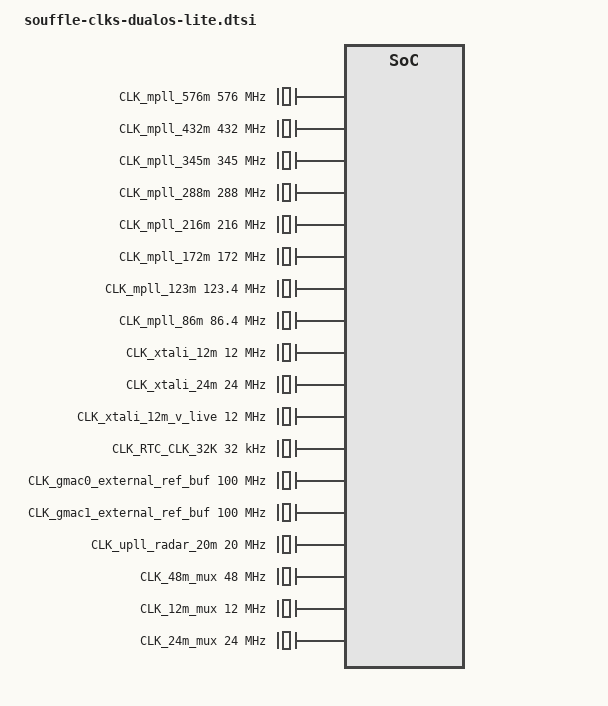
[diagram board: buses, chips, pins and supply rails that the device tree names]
/*
* souffle-clks-dualos-lite.dtsi- Sigmastar
*
* Copyright (c) [2019~2020] SigmaStar Technology.
*
*
* This software is licensed under the terms of the GNU General Public
* License version 2, as published by the Free Software Foundation, and
* may be copied, distributed, and modified under those terms.
*
* This program is distributed in the hope that it will be useful,
* but WITHOUT ANY WARRANTY; without even the implied warranty of
* MERCHANTABILITY or FITNESS FOR A PARTICULAR PURPOSE.  See the
* GNU General Public License version 2 for more details.
*
*/

/* generated by CLK_DT_GEN_5.2 */
/* CLK FILENAME: infinity6f\infinity6f_clock_table.xls */
/* REG FILENAME: infinity6f\infinity6f_reg_CLKGEN.xls, infinity6f\infinity6f_reg_CLKGEN2.xls, infinity6f\infinity6f_reg_pm_sleep.xls, infinity6f\infinity6f_reg_block.xls, infinity6f\infinity6f_reg_chiptop.xls */

CLK_VOID: CLK_VOID {
    #clock-cells = <0>;
    compatible = "fixed-clock";
    clock-frequency = <1>;
};

CLK_mpll_576m: CLK_mpll_576m {
    #clock-cells = <0>;
    compatible = "fixed-clock";
    clock-frequency = <576000000>;
};

CLK_upll_960m: CLK_upll_960m {
    #clock-cells = <0>;
    compatible = "sstar,complex-clock";
    clocks = <&CLK_VOID>;
    clock-frequency = <960000000>;
};

CLK_upll_480m: CLK_upll_480m {
    #clock-cells = <0>;
    compatible = "sstar,complex-clock";
    clocks = <&CLK_upll_960m>;
    clock-frequency = <480000000>;
};

CLK_mpll_432m: CLK_mpll_432m {
    #clock-cells = <0>;
    compatible = "fixed-clock";
    clock-frequency = <432000000>;
};

CLK_upll_384m: CLK_upll_384m {
    #clock-cells = <0>;
    compatible = "sstar,complex-clock";
    clocks = <&CLK_upll_960m>;
    clock-frequency = <384000000>;
};

CLK_aupll_384m: CLK_aupll_384m {
    #clock-cells = <0>;
    compatible = "sstar,complex-clock";
    clocks = <&CLK_mpll_432m>;
    clock-frequency = <384000000>;
};

CLK_bachpll_384m: CLK_bachpll_384m {
    #clock-cells = <0>;
    compatible = "sstar,complex-clock";
    clocks = <&CLK_VOID>;
    clock-frequency = <384000000>;
};

CLK_mpll_345m: CLK_mpll_345m {
    #clock-cells = <0>;
    compatible = "fixed-clock";
    clock-frequency = <345000000>;
};

CLK_upll_320m: CLK_upll_320m {
    #clock-cells = <0>;
    compatible = "sstar,complex-clock";
    clocks = <&CLK_upll_960m>;
    clock-frequency = <320000000>;
};

CLK_mpll_288m: CLK_mpll_288m {
    #clock-cells = <0>;
    compatible = "fixed-clock";
    clock-frequency = <288000000>;
};

CLK_mpll_216m: CLK_mpll_216m {
    #clock-cells = <0>;
    compatible = "fixed-clock";
    clock-frequency = <216000000>;
};

CLK_mpll_172m: CLK_mpll_172m {
    #clock-cells = <0>;
    compatible = "fixed-clock";
    clock-frequency = <172000000>;
};

CLK_mpll_123m: CLK_mpll_123m {
    #clock-cells = <0>;
    compatible = "fixed-clock";
    clock-frequency = <123400000>;
};

CLK_mpll_86m: CLK_mpll_86m {
    #clock-cells = <0>;
    compatible = "fixed-clock";
    clock-frequency = <86400000>;
};

CLK_upll_480m_div2: CLK_upll_480m_div2 {
    #clock-cells = <0>;
    compatible = "fixed-factor-clock";
    clocks = <&CLK_upll_480m>;
    clock-div = <2>;
    clock-mult = <1>;
};

CLK_upll_384m_div2: CLK_upll_384m_div2 {
    #clock-cells = <0>;
    compatible = "fixed-factor-clock";
    clocks = <&CLK_upll_384m>;
    clock-div = <2>;
    clock-mult = <1>;
};

CLK_mpll_288m_div2: CLK_mpll_288m_div2 {
    #clock-cells = <0>;
    compatible = "fixed-factor-clock";
    clocks = <&CLK_mpll_288m>;
    clock-div = <2>;
    clock-mult = <1>;
};

CLK_mpll_288m_div4: CLK_mpll_288m_div4 {
    #clock-cells = <0>;
    compatible = "fixed-factor-clock";
    clocks = <&CLK_mpll_288m>;
    clock-div = <4>;
    clock-mult = <1>;
};

CLK_mpll_288m_div8: CLK_mpll_288m_div8 {
    #clock-cells = <0>;
    compatible = "fixed-factor-clock";
    clocks = <&CLK_mpll_288m>;
    clock-div = <8>;
    clock-mult = <1>;
};

CLK_mpll_432m_div4: CLK_mpll_432m_div4 {
    #clock-cells = <0>;
    compatible = "fixed-factor-clock";
    clocks = <&CLK_mpll_432m>;
    clock-div = <4>;
    clock-mult = <1>;
};

CLK_mpll_432m_div8: CLK_mpll_432m_div8 {
    #clock-cells = <0>;
    compatible = "fixed-factor-clock";
    clocks = <&CLK_mpll_432m>;
    clock-div = <8>;
    clock-mult = <1>;
};

/* CLK_mpll_432m_div16: CLK_mpll_432m_div16 {
    #clock-cells = <0>;
    compatible = "fixed-factor-clock";
    clocks = <&CLK_mpll_432m>;
    clock-div = <16>;
    clock-mult = <1>;
}; */

/* CLK_mpll_123m_div2: CLK_mpll_123m_div2 {
    #clock-cells = <0>;
    compatible = "fixed-factor-clock";
    clocks = <&CLK_mpll_123m>;
    clock-div = <2>;
    clock-mult = <1>;
}; */

CLK_mpll_86m_div2: CLK_mpll_86m_div2 {
    #clock-cells = <0>;
    compatible = "fixed-factor-clock";
    clocks = <&CLK_mpll_86m>;
    clock-div = <2>;
    clock-mult = <1>;
};

/* CLK_mpll_86m_div4: CLK_mpll_86m_div4 {
    #clock-cells = <0>;
    compatible = "fixed-factor-clock";
    clocks = <&CLK_mpll_86m>;
    clock-div = <4>;
    clock-mult = <1>;
}; */

/* CLK_mpll_86m_div16: CLK_mpll_86m_div16 {
    #clock-cells = <0>;
    compatible = "fixed-factor-clock";
    clocks = <&CLK_mpll_86m>;
    clock-div = <16>;
    clock-mult = <1>;
}; */

CLK_upll_384m_div8: CLK_upll_384m_div8 {
    #clock-cells = <0>;
    compatible = "fixed-factor-clock";
    clocks = <&CLK_upll_384m>;
    clock-div = <8>;
    clock-mult = <1>;
};

CLK_upll_320m_div2: CLK_upll_320m_div2 {
    #clock-cells = <0>;
    compatible = "fixed-factor-clock";
    clocks = <&CLK_upll_320m>;
    clock-div = <2>;
    clock-mult = <1>;
};

CLK_upll_320m_div8: CLK_upll_320m_div8 {
    #clock-cells = <0>;
    compatible = "fixed-factor-clock";
    clocks = <&CLK_upll_320m>;
    clock-div = <8>;
    clock-mult = <1>;
};

CLK_upll_320m_div10: CLK_upll_320m_div10 {
    #clock-cells = <0>;
    compatible = "fixed-factor-clock";
    clocks = <&CLK_upll_320m>;
    clock-div = <10>;
    clock-mult = <1>;
};

CLK_upll_320m_div16: CLK_upll_320m_div16 {
    #clock-cells = <0>;
    compatible = "fixed-factor-clock";
    clocks = <&CLK_upll_320m>;
    clock-div = <16>;
    clock-mult = <1>;
};

CLK_upll_320m_div20: CLK_upll_320m_div20 {
    #clock-cells = <0>;
    compatible = "fixed-factor-clock";
    clocks = <&CLK_upll_320m>;
    clock-div = <20>;
    clock-mult = <1>;
};

CLK_xtali_12m: CLK_xtali_12m {
    #clock-cells = <0>;
    compatible = "fixed-clock";
    clock-frequency = <12000000>;
};

CLK_xtali_12m_div2: CLK_xtali_12m_div2 {
    #clock-cells = <0>;
    compatible = "fixed-factor-clock";
    clocks = <&CLK_xtali_12m>;
    clock-div = <2>;
    clock-mult = <1>;
};

CLK_xtali_12m_div4: CLK_xtali_12m_div4 {
    #clock-cells = <0>;
    compatible = "fixed-factor-clock";
    clocks = <&CLK_xtali_12m>;
    clock-div = <4>;
    clock-mult = <1>;
};

CLK_xtali_12m_div8: CLK_xtali_12m_div8 {
    #clock-cells = <0>;
    compatible = "fixed-factor-clock";
    clocks = <&CLK_xtali_12m>;
    clock-div = <8>;
    clock-mult = <1>;
};

CLK_xtali_12m_div16: CLK_xtali_12m_div16 {
    #clock-cells = <0>;
    compatible = "fixed-factor-clock";
    clocks = <&CLK_xtali_12m>;
    clock-div = <16>;
    clock-mult = <1>;
};

CLK_xtali_12m_div40: CLK_xtali_12m_div40 {
    #clock-cells = <0>;
    compatible = "fixed-factor-clock";
    clocks = <&CLK_xtali_12m>;
    clock-div = <40>;
    clock-mult = <1>;
};

/* CLK_xtali_12m_div64: CLK_xtali_12m_div64 {
    #clock-cells = <0>;
    compatible = "fixed-factor-clock";
    clocks = <&CLK_xtali_12m>;
    clock-div = <64>;
    clock-mult = <1>;
}; */

/* CLK_xtali_12m_div128: CLK_xtali_12m_div128 {
    #clock-cells = <0>;
    compatible = "fixed-factor-clock";
    clocks = <&CLK_xtali_12m>;
    clock-div = <128>;
    clock-mult = <1>;
}; */

CLK_xtali_12m_div375: CLK_xtali_12m_div375 {
    #clock-cells = <0>;
    compatible = "fixed-factor-clock";
    clocks = <&CLK_xtali_12m>;
    clock-div = <375>;
    clock-mult = <1>;
};

CLK_xtali_24m: CLK_xtali_24m {
    #clock-cells = <0>;
    compatible = "fixed-clock";
    clock-frequency = <24000000>;
};

CLK_xtali_12m_v_live: CLK_xtali_12m_v_live {
    #clock-cells = <0>;
    compatible = "fixed-clock";
    clock-frequency = <12000000>;
};

CLK_RTC_CLK_32K: CLK_RTC_CLK_32K {
    #clock-cells = <0>;
    compatible = "fixed-clock";
    clock-frequency = <32000>;
};

/* CLK_pm_riu_w_clk_in: CLK_pm_riu_w_clk_in {
    #clock-cells = <0>;
    compatible = "fixed-clock";
    clock-frequency = <108000000>;
}; */

CLK_gmacpll_top: CLK_gmacpll_top {
    #clock-cells = <0>;
    compatible = "sstar,complex-clock";
    clocks = <&CLK_VOID>;
    clock-frequency = <3000000000>;
};

CLK_gmacpll_250: CLK_gmacpll_250 {
    #clock-cells = <0>;
    compatible = "fixed-factor-clock";
    clocks = <&CLK_gmacpll_top>;
    clock-div = <12>;
    clock-mult = <1>;
    clock-frequency = <250000000>;
};

CLK_gmacpll_250_div2: CLK_gmacpll_250_div2 {
    #clock-cells = <0>;
    compatible = "fixed-factor-clock";
    clocks = <&CLK_gmacpll_250>;
    clock-div = <2>;
    clock-mult = <1>;
};

CLK_gmacpll_250_div5: CLK_gmacpll_250_div5 {
    #clock-cells = <0>;
    compatible = "fixed-factor-clock";
    clocks = <&CLK_gmacpll_250>;
    clock-div = <5>;
    clock-mult = <1>;
};

CLK_gmacpll_250_div100: CLK_gmacpll_250_div100 {
    #clock-cells = <0>;
    compatible = "fixed-factor-clock";
    clocks = <&CLK_gmacpll_250>;
    clock-div = <100>;
    clock-mult = <1>;
};

CLK_gmacpll_25a: CLK_gmacpll_25a {
    #clock-cells = <0>;
    compatible = "fixed-factor-clock";
    clocks = <&CLK_gmacpll_top>;
    clock-div = <120>;
    clock-mult = <1>;
    clock-frequency = <25000000>;
};

CLK_gmacpll_25b: CLK_gmacpll_25b {
    #clock-cells = <0>;
    compatible = "fixed-factor-clock";
    clocks = <&CLK_gmacpll_top>;
    clock-div = <120>;
    clock-mult = <1>;
    clock-frequency = <25000000>;
};

CLK_isppll_clk: CLK_isppll_clk {
    #clock-cells = <0>;
    compatible = "sstar,complex-clock";
    clocks = <&CLK_VOID>;
};

CLK_isppll_clk_div2: CLK_isppll_clk_div2 {
    #clock-cells = <0>;
    compatible = "fixed-factor-clock";
    clocks = <&CLK_isppll_clk>;
    clock-div = <2>;
    clock-mult = <1>;
};

CLK_isppll_clk_div4: CLK_isppll_clk_div4 {
    #clock-cells = <0>;
    compatible = "fixed-factor-clock";
    clocks = <&CLK_isppll_clk>;
    clock-div = <4>;
    clock-mult = <1>;
};

CLK_isppll_clk_div8: CLK_isppll_clk_div8 {
    #clock-cells = <0>;
    compatible = "fixed-factor-clock";
    clocks = <&CLK_isppll_clk>;
    clock-div = <8>;
    clock-mult = <1>;
};

CLK_isppll_clk_div16: CLK_isppll_clk_div16 {
    #clock-cells = <0>;
    compatible = "fixed-factor-clock";
    clocks = <&CLK_isppll_clk>;
    clock-div = <16>;
    clock-mult = <1>;
};

CLK_ipupll_clk: CLK_ipupll_clk {
    #clock-cells = <0>;
    compatible = "sstar,complex-clock";
    clocks = <&CLK_mpll_432m>;
};

CLK_miupll_clk: CLK_miupll_clk {
    #clock-cells = <0>;
    compatible = "fixed-clock";
    clock-frequency = <466000000>;
};

/* CLK_ddrpll_clk: CLK_ddrpll_clk {
    #clock-cells = <0>;
    compatible = "fixed-clock";
    clock-frequency = <1864000000>;
}; */

CLK_venpll_clk: CLK_venpll_clk {
    #clock-cells = <0>;
    compatible = "sstar,complex-clock";
    clocks = <&CLK_VOID>;
};

CLK_riscvpll_clk: CLK_riscvpll_clk {
    #clock-cells = <0>;
    compatible = "sstar,complex-clock";
    clocks = <&CLK_VOID>;
};

CLK_disppll_clk: CLK_disppll_clk {
    #clock-cells = <0>;
    compatible = "sstar,complex-clock";
    clocks = <&CLK_VOID>;
};

CLK_ven_pll: CLK_ven_pll {
    #clock-cells = <0>;
    compatible = "fixed-clock";
    clock-frequency = <500000000>;
};

CLK_cpu_pll: CLK_cpu_pll {
    #clock-cells = <0>;
    compatible = "sstar,complex-clock";
    clocks = <&CLK_mpll_432m>;
};

CLK_disppll_clk_div2: CLK_disppll_clk_div2 {
    #clock-cells = <0>;
    compatible = "fixed-factor-clock";
    clocks = <&CLK_disppll_clk>;
    clock-div = <2>;
    clock-mult = <1>;
};

CLK_disppll_clk_div4: CLK_disppll_clk_div4 {
    #clock-cells = <0>;
    compatible = "fixed-factor-clock";
    clocks = <&CLK_disppll_clk>;
    clock-div = <4>;
    clock-mult = <1>;
};

CLK_disppll_clk_div8: CLK_disppll_clk_div8 {
    #clock-cells = <0>;
    compatible = "fixed-factor-clock";
    clocks = <&CLK_disppll_clk>;
    clock-div = <8>;
    clock-mult = <1>;
};

/* CLK_riu_w_clk_in: CLK_riu_w_clk_in {
    #clock-cells = <0>;
    compatible = "fixed-factor-clock";
    clocks = <&CLK_mcu>;
    clock-div = <1>;
    clock-mult = <1>;
}; */

/* CLK_riu_w_clk_top: CLK_riu_w_clk_top {
    #clock-cells = <0>;
    compatible = "fixed-factor-clock";
    clocks = <&CLK_mcu>;
    clock-div = <1>;
    clock-mult = <1>;
}; */

/* CLK_riu_w_clk_sc_gp: CLK_riu_w_clk_sc_gp {
    #clock-cells = <0>;
    compatible = "fixed-factor-clock";
    clocks = <&CLK_mcu>;
    clock-div = <1>;
    clock-mult = <1>;
}; */

/* CLK_riu_w_clk_vhe_gp: CLK_riu_w_clk_vhe_gp {
    #clock-cells = <0>;
    compatible = "fixed-factor-clock";
    clocks = <&CLK_mcu>;
    clock-div = <1>;
    clock-mult = <1>;
}; */

/* CLK_riu_w_clk_hemcu_gp: CLK_riu_w_clk_hemcu_gp {
    #clock-cells = <0>;
    compatible = "fixed-factor-clock";
    clocks = <&CLK_mcu>;
    clock-div = <1>;
    clock-mult = <1>;
}; */

/* CLK_riu_w_clk_mipi_if_gp: CLK_riu_w_clk_mipi_if_gp {
    #clock-cells = <0>;
    compatible = "fixed-factor-clock";
    clocks = <&CLK_mcu>;
    clock-div = <1>;
    clock-mult = <1>;
}; */

/* CLK_riu_w_clk_mcu_if_gp: CLK_riu_w_clk_mcu_if_gp {
    #clock-cells = <0>;
    compatible = "fixed-factor-clock";
    clocks = <&CLK_mcu>;
    clock-div = <1>;
    clock-mult = <1>;
}; */

CLK_spi_synth_pll: CLK_spi_synth_pll {
    #clock-cells = <0>;
    compatible = "fixed-clock";
    clock-frequency = <266000000>;
};

CLK_fuart_synth_out: CLK_fuart_synth_out {
    #clock-cells = <0>;
    compatible = "sstar,complex-clock";
    clocks = <&CLK_fuart_synth_in>;
};

CLK_fuart0_synth_out: CLK_fuart0_synth_out {
    #clock-cells = <0>;
    compatible = "sstar,complex-clock";
    clocks = <&CLK_fuart0_synth_in>;
};

CLK_fuart1_synth_out: CLK_fuart1_synth_out {
    #clock-cells = <0>;
    compatible = "sstar,complex-clock";
    clocks = <&CLK_fuart1_synth_in>;
};

CLK_fuart2_synth_out: CLK_fuart2_synth_out {
    #clock-cells = <0>;
    compatible = "sstar,complex-clock";
    clocks = <&CLK_fuart2_synth_in>;
};

CLK_fuart3_synth_out: CLK_fuart3_synth_out {
    #clock-cells = <0>;
    compatible = "sstar,complex-clock";
    clocks = <&CLK_fuart3_synth_in>;
};

CLK_fuart4_synth_out: CLK_fuart4_synth_out {
    #clock-cells = <0>;
    compatible = "sstar,complex-clock";
    clocks = <&CLK_fuart4_synth_in>;
};

CLK_fuart5_synth_out: CLK_fuart5_synth_out {
    #clock-cells = <0>;
    compatible = "sstar,complex-clock";
    clocks = <&CLK_fuart5_synth_in>;
};

CLK_fuart6_synth_out: CLK_fuart6_synth_out {
    #clock-cells = <0>;
    compatible = "sstar,complex-clock";
    clocks = <&CLK_fuart6_synth_in>;
};

CLK_fuart7_synth_out: CLK_fuart7_synth_out {
    #clock-cells = <0>;
    compatible = "sstar,complex-clock";
    clocks = <&CLK_fuart7_synth_in>;
};

CLK_miu: CLK_miu {
    #clock-cells = <0>;
    compatible = "fixed-clock";
    clock-frequency = <466000000>;
};

CLK_miu_p: CLK_miu_p {
    #clock-cells = <0>;
    compatible = "fixed-factor-clock";
    clocks = <&CLK_miu>;
    clock-div = <1>;
    clock-mult = <1>;
};

/* CLK_mspi0_p: CLK_mspi0_p {
    #clock-cells = <0>;
    compatible = "fixed-factor-clock";
    clocks = <&CLK_mspi0>;
    clock-div = <1>;
    clock-mult = <1>;
}; */

/* CLK_miu_vhe_gp_p: CLK_miu_vhe_gp_p {
    #clock-cells = <0>;
    compatible = "fixed-factor-clock";
    clocks = <&CLK_miu>;
    clock-div = <1>;
    clock-mult = <1>;
}; */

/* CLK_miu_sc_gp_p: CLK_miu_sc_gp_p {
    #clock-cells = <0>;
    compatible = "fixed-factor-clock";
    clocks = <&CLK_miu>;
    clock-div = <1>;
    clock-mult = <1>;
}; */

/* CLK_miu_isp_gp_p: CLK_miu_isp_gp_p {
    #clock-cells = <0>;
    compatible = "fixed-factor-clock";
    clocks = <&CLK_miu>;
    clock-div = <1>;
    clock-mult = <1>;
}; */

/* CLK_miu2x_p: CLK_miu2x_p {
    #clock-cells = <0>;
    compatible = "fixed-factor-clock";
    clocks = <&CLK_miu>;
    clock-div = <1>;
    clock-mult = <1>;
}; */

/* CLK_mcu_p: CLK_mcu_p {
    #clock-cells = <0>;
    compatible = "fixed-factor-clock";
    clocks = <&CLK_mcu>;
    clock-div = <1>;
    clock-mult = <1>;
}; */

/* CLK_mcu_pm_p: CLK_mcu_pm_p {
    #clock-cells = <0>;
    compatible = "fixed-factor-clock";
    clocks = <&CLK_mcu_pm>;
    clock-div = <1>;
    clock-mult = <1>;
}; */

/* CLK_isp_p: CLK_isp_p {
    #clock-cells = <0>;
    compatible = "fixed-factor-clock";
    clocks = <&CLK_isp>;
    clock-div = <1>;
    clock-mult = <1>;
}; */

/* CLK_fclk1_p: CLK_fclk1_p {
    #clock-cells = <0>;
    compatible = "fixed-factor-clock";
    clocks = <&CLK_fclk1>;
    clock-div = <1>;
    clock-mult = <1>;
}; */

/* CLK_fclk2_p: CLK_fclk2_p {
    #clock-cells = <0>;
    compatible = "fixed-factor-clock";
    clocks = <&CLK_fclk1>;
    clock-div = <1>;
    clock-mult = <1>;
}; */

CLK_sd_1x_p: CLK_sd_1x_p {
    #clock-cells = <0>;
    compatible = "sstar,complex-clock";
    clocks = <&CLK_VOID>;
    clock-frequency = <110000000>;
};

CLK_sd_2x_p: CLK_sd_2x_p {
    #clock-cells = <0>;
    compatible = "fixed-clock";
    clock-frequency = <220000000>;
};

CLK_fcie_1x_p: CLK_fcie_1x_p {
    #clock-cells = <0>;
    compatible = "sstar,complex-clock";
    clocks = <&CLK_VOID>;
};

CLK_fcie_2x_p: CLK_fcie_2x_p {
    #clock-cells = <0>;
    compatible = "sstar,complex-clock";
    clocks = <&CLK_VOID>;
};

CLK_otp_p: CLK_otp_p {
    #clock-cells = <0>;
    compatible = "fixed-clock";
    clock-frequency = <12000000>;
};

/* CLK_sr_mclk: CLK_sr_mclk {
    #clock-cells = <0>;
    compatible = "fixed-clock";
    clock-frequency = <75000000>;
}; */

/* CLK_tck_buf: CLK_tck_buf {
    #clock-cells = <0>;
    compatible = "fixed-clock";
    clock-frequency = <50000000>;
}; */

/* CLK_eth_buf: CLK_eth_buf {
    #clock-cells = <0>;
    compatible = "fixed-clock";
    clock-frequency = <125000000>;
}; */

/* CLK_rmii_buf: CLK_rmii_buf {
    #clock-cells = <0>;
    compatible = "fixed-clock";
    clock-frequency = <125000000>;
}; */

CLK_emac_testrx125_in_lan: CLK_emac_testrx125_in_lan {
    #clock-cells = <0>;
    compatible = "fixed-clock";
    clock-frequency = <125000000>;
};

CLK_gmac0_external_ref_buf: CLK_gmac0_external_ref_buf {
    #clock-cells = <0>;
    compatible = "fixed-clock";
    clock-frequency = <100000000>;
};

CLK_gmac1_external_ref_buf: CLK_gmac1_external_ref_buf {
    #clock-cells = <0>;
    compatible = "fixed-clock";
    clock-frequency = <100000000>;
};

CLK_upll_384m_div4: CLK_upll_384m_div4 {
    #clock-cells = <0>;
    compatible = "fixed-factor-clock";
    clocks = <&CLK_upll_384m>;
    clock-div = <4>;
    clock-mult = <1>;
};

CLK_upll_20m: CLK_upll_20m {
    #clock-cells = <0>;
    compatible = "sstar,complex-clock";
    clocks = <&CLK_upll_960m>;
    clock-frequency = <20000000>;
};

CLK_upll_radar_20m: CLK_upll_radar_20m {
    #clock-cells = <0>;
    compatible = "fixed-clock";
    clock-frequency = <20000000>;
};

CLK_48m_mux: CLK_48m_mux {
    #clock-cells = <0>;
    compatible = "fixed-clock";
    clock-frequency = <48000000>;
};

CLK_12m_mux: CLK_12m_mux {
    #clock-cells = <0>;
    compatible = "fixed-clock";
    clock-frequency = <12000000>;
};

CLK_12m_mux_div2: CLK_12m_mux_div2 {
    #clock-cells = <0>;
    compatible = "fixed-factor-clock";
    clocks = <&CLK_12m_mux>;
    clock-div = <2>;
    clock-mult = <1>;
};

CLK_12m_mux_div4: CLK_12m_mux_div4 {
    #clock-cells = <0>;
    compatible = "fixed-factor-clock";
    clocks = <&CLK_12m_mux>;
    clock-div = <4>;
    clock-mult = <1>;
};

CLK_12m_mux_div8: CLK_12m_mux_div8 {
    #clock-cells = <0>;
    compatible = "fixed-factor-clock";
    clocks = <&CLK_12m_mux>;
    clock-div = <8>;
    clock-mult = <1>;
};

CLK_12m_mux_div16: CLK_12m_mux_div16 {
    #clock-cells = <0>;
    compatible = "fixed-factor-clock";
    clocks = <&CLK_12m_mux>;
    clock-div = <16>;
    clock-mult = <1>;
};

CLK_24m_mux: CLK_24m_mux {
    #clock-cells = <0>;
    compatible = "fixed-clock";
    clock-frequency = <24000000>;
};

#if (HAL_CLK_RTCPLL_BY_CCF)
CLK_rtcpll_clk: CLK_rtcpll_clk {
    #clock-cells = <0>;
    compatible = "sstar,complex-clock";
    clocks = <&CLK_VOID>;
};
#else
CLK_rtcpll_clk: CLK_rtcpll_clk {
    #clock-cells = <0>;
    compatible = "fixed-clock";
    clock-frequency = <196600000>;
};
#endif

CLK_rtcpll_clk_div2: CLK_rtcpll_clk_div2 {
    #clock-cells = <0>;
    compatible = "fixed-factor-clock";
    clocks = <&CLK_rtcpll_clk>;
    clock-div = <2>;
    clock-mult = <1>;
};

CLK_rtcpll_clk_div4: CLK_rtcpll_clk_div4 {
    #clock-cells = <0>;
    compatible = "fixed-factor-clock";
    clocks = <&CLK_rtcpll_clk>;
    clock-div = <4>;
    clock-mult = <1>;
};

CLK_rtcpll_clk_div6: CLK_rtcpll_clk_div6 {
    #clock-cells = <0>;
    compatible = "fixed-factor-clock";
    clocks = <&CLK_rtcpll_clk>;
    clock-div = <6>;
    clock-mult = <1>;
};

CLK_rtcpll_clk_div8: CLK_rtcpll_clk_div8 {
    #clock-cells = <0>;
    compatible = "fixed-factor-clock";
    clocks = <&CLK_rtcpll_clk>;
    clock-div = <8>;
    clock-mult = <1>;
};

CLK_rtcpll_clk_div16: CLK_rtcpll_clk_div16 {
    #clock-cells = <0>;
    compatible = "fixed-factor-clock";
    clocks = <&CLK_rtcpll_clk>;
    clock-div = <16>;
    clock-mult = <1>;
};

CLK_rtcpll_clk_div32: CLK_rtcpll_clk_div32 {
    #clock-cells = <0>;
    compatible = "fixed-factor-clock";
    clocks = <&CLK_rtcpll_clk>;
    clock-div = <32>;
    clock-mult = <1>;
};

CLK_rtcpll_clk_div48: CLK_rtcpll_clk_div48 {
    #clock-cells = <0>;
    compatible = "fixed-factor-clock";
    clocks = <&CLK_rtcpll_clk>;
    clock-div = <48>;
    clock-mult = <1>;
};

CLK_rtcpll_clk_div64: CLK_rtcpll_clk_div64 {
    #clock-cells = <0>;
    compatible = "fixed-factor-clock";
    clocks = <&CLK_rtcpll_clk>;
    clock-div = <64>;
    clock-mult = <1>;
};

CLK_rtcpll_clk_div96: CLK_rtcpll_clk_div96 {
    #clock-cells = <0>;
    compatible = "fixed-factor-clock";
    clocks = <&CLK_rtcpll_clk>;
    clock-div = <96>;
    clock-mult = <1>;
};

CLK_rtcpll_clk_div128: CLK_rtcpll_clk_div128 {
    #clock-cells = <0>;
    compatible = "fixed-factor-clock";
    clocks = <&CLK_rtcpll_clk>;
    clock-div = <128>;
    clock-mult = <1>;
};

CLK_rtcpll_clk_div256: CLK_rtcpll_clk_div256 {
    #clock-cells = <0>;
    compatible = "fixed-factor-clock";
    clocks = <&CLK_rtcpll_clk>;
    clock-div = <256>;
    clock-mult = <1>;
};

CLK_rtcpll_clk_div192: CLK_rtcpll_clk_div192 {
    #clock-cells = <0>;
    compatible = "fixed-factor-clock";
    clocks = <&CLK_rtcpll_clk>;
    clock-div = <192>;
    clock-mult = <1>;
};

CLK_rtcpll_clk_div384: CLK_rtcpll_clk_div384 {
    #clock-cells = <0>;
    compatible = "fixed-factor-clock";
    clocks = <&CLK_rtcpll_clk>;
    clock-div = <384>;
    clock-mult = <1>;
};

/* CLK_ddr_syn: CLK_ddr_syn {
    #clock-cells = <0>;
    compatible = "sstar,composite-clock";
    clocks = <&CLK_mpll_432m>,<&CLK_mpll_216m>,<&CLK_xtali_12m>,<&CLK_VOID>;
    reg = <REG_CKG_DDR_SYN_BASE 0x4>;
    mux-shift = <2>;  //2+REG_CKG_DDR_SYN_OFFSET
    mux-width = <2>;
    gate-shift = <0>;  //0+REG_CKG_DDR_SYN_OFFSET
    auto-enable = <1>;
}; */

/* CLK_miu_rec: CLK_miu_rec {
    #clock-cells = <0>;
    compatible = "sstar,composite-clock";
    clocks = <&CLK_xtali_12m_div8>,<&CLK_xtali_12m_div16>,<&CLK_xtali_12m_div64>,<&CLK_xtali_12m_div128>;
    reg = <REG_CKG_MIU_REC_BASE 0x4>;
    mux-shift = <2>;  //2+REG_CKG_MIU_REC_OFFSET
    mux-width = <2>;
    gate-shift = <0>;  //0+REG_CKG_MIU_REC_OFFSET
    auto-enable = <1>;
}; */

CLK_mcu: CLK_mcu {
    #clock-cells = <0>;
    compatible = "sstar,composite-clock";
    clocks = <&CLK_mpll_216m>,<&CLK_mpll_432m>,<&CLK_upll_320m>,<&CLK_upll_480m_div2>,<&CLK_upll_384m>,<&CLK_mpll_288m>,<&CLK_mpll_172m>,<&CLK_mpll_432m_div4>;
    reg = <REG_CKG_MCU_BASE 0x4>;
    mux-shift = <2>;  //2+REG_CKG_MCU_OFFSET
    mux-width = <3>;
    gate-shift = <0>;  //0+REG_CKG_MCU_OFFSET
    glitch-shift = <5>;  //5+REG_CKG_MCU_OFFSET
    auto-enable = <1>;
};

/* CLK_riubrdg: CLK_riubrdg {
    #clock-cells = <0>;
    compatible = "sstar,composite-clock";
    clocks = <&CLK_mcu_p>,<&CLK_VOID>,<&CLK_VOID>,<&CLK_VOID>;
    reg = <REG_CKG_RIUBRDG_BASE 0x4>;
    mux-shift = <10>;  //2+REG_CKG_RIUBRDG_OFFSET
    mux-width = <2>;
    gate-shift = <8>;  //0+REG_CKG_RIUBRDG_OFFSET
    auto-enable = <1>;
}; */

CLK_spi: CLK_spi {
    #clock-cells = <0>;
    compatible = "sstar,composite-clock";
    clocks = <&CLK_xtali_24m>,<&CLK_mpll_86m>,<&CLK_mpll_432m_div4>,<&CLK_mpll_86m_div2>,<&CLK_mpll_432m_div8>,<&CLK_VOID>,<&CLK_VOID>,<&CLK_VOID>;
    reg = <REG_CKG_SPI_BASE 0x4>;
    mux-shift = <2>;  //2+REG_CKG_SPI_OFFSET
    mux-width = <3>;
    gate-shift = <0>;  //0+REG_CKG_SPI_OFFSET
    auto-enable = <1>;
};

CLK_pwm: CLK_pwm {
    #clock-cells = <0>;
    compatible = "sstar,composite-clock";
    clocks = <&CLK_xtali_12m>,<&CLK_xtali_12m_div2>,<&CLK_xtali_12m_div4>,<&CLK_xtali_12m_div8>,<&CLK_xtali_12m_div16>,<&CLK_mpll_86m>,<&CLK_xtali_24m>,<&CLK_VOID>;
    reg = <REG_CKG_PWM_BASE 0x4>;
    mux-shift = <10>;  //2+REG_CKG_PWM_OFFSET
    mux-width = <3>;
    gate-shift = <8>;  //0+REG_CKG_PWM_OFFSET
    auto-enable = <1>;
};

CLK_fuart_synth_in: CLK_fuart_synth_in {
    #clock-cells = <0>;
    compatible = "sstar,composite-clock";
    clocks = <&CLK_mpll_432m>,<&CLK_mpll_216m>,<&CLK_VOID>,<&CLK_VOID>;
    reg = <REG_CKG_FUART_SYNTH_IN_BASE 0x4>;
    mux-shift = <6>;  //2+REG_CKG_FUART_SYNTH_IN_OFFSET
    mux-width = <2>;
    gate-shift = <4>;  //0+REG_CKG_FUART_SYNTH_IN_OFFSET
    auto-enable = <1>;
};

CLK_fuart0_synth_in: CLK_fuart0_synth_in {
    #clock-cells = <0>;
    compatible = "sstar,composite-clock";
    clocks = <&CLK_mpll_432m>,<&CLK_mpll_216m>,<&CLK_VOID>,<&CLK_VOID>;
    reg = <REG_CKG_FUART0_SYNTH_IN_BASE 0x4>;
    mux-shift = <6>;  //2+REG_CKG_FUART0_SYNTH_IN_OFFSET
    mux-width = <2>;
    gate-shift = <4>;  //0+REG_CKG_FUART0_SYNTH_IN_OFFSET
    auto-enable = <1>;
};

CLK_fuart1_synth_in: CLK_fuart1_synth_in {
    #clock-cells = <0>;
    compatible = "sstar,composite-clock";
    clocks = <&CLK_mpll_432m>,<&CLK_mpll_216m>,<&CLK_VOID>,<&CLK_VOID>;
    reg = <REG_CKG_FUART1_SYNTH_IN_BASE 0x4>;
    mux-shift = <6>;  //2+REG_CKG_FUART1_SYNTH_IN_OFFSET
    mux-width = <2>;
    gate-shift = <4>;  //0+REG_CKG_FUART1_SYNTH_IN_OFFSET
    auto-enable = <1>;
};

CLK_fuart2_synth_in: CLK_fuart2_synth_in {
    #clock-cells = <0>;
    compatible = "sstar,composite-clock";
    clocks = <&CLK_mpll_432m>,<&CLK_mpll_216m>,<&CLK_VOID>,<&CLK_VOID>;
    reg = <REG_CKG_FUART2_SYNTH_IN_BASE 0x4>;
    mux-shift = <6>;  //2+REG_CKG_FUART2_SYNTH_IN_OFFSET
    mux-width = <2>;
    gate-shift = <4>;  //0+REG_CKG_FUART2_SYNTH_IN_OFFSET
    auto-enable = <1>;
};

CLK_fuart3_synth_in: CLK_fuart3_synth_in {
    #clock-cells = <0>;
    compatible = "sstar,composite-clock";
    clocks = <&CLK_mpll_432m>,<&CLK_mpll_216m>,<&CLK_VOID>,<&CLK_VOID>;
    reg = <REG_CKG_FUART3_SYNTH_IN_BASE 0x4>;
    mux-shift = <6>;  //2+REG_CKG_FUART3_SYNTH_IN_OFFSET
    mux-width = <2>;
    gate-shift = <4>;  //0+REG_CKG_FUART3_SYNTH_IN_OFFSET
    auto-enable = <1>;
};

CLK_fuart4_synth_in: CLK_fuart4_synth_in {
    #clock-cells = <0>;
    compatible = "sstar,composite-clock";
    clocks = <&CLK_mpll_432m>,<&CLK_mpll_216m>,<&CLK_VOID>,<&CLK_VOID>;
    reg = <REG_CKG_FUART4_SYNTH_IN_BASE 0x4>;
    mux-shift = <6>;  //2+REG_CKG_FUART4_SYNTH_IN_OFFSET
    mux-width = <2>;
    gate-shift = <4>;  //0+REG_CKG_FUART4_SYNTH_IN_OFFSET
    auto-enable = <1>;
};

CLK_fuart5_synth_in: CLK_fuart5_synth_in {
    #clock-cells = <0>;
    compatible = "sstar,composite-clock";
    clocks = <&CLK_mpll_432m>,<&CLK_mpll_216m>,<&CLK_VOID>,<&CLK_VOID>;
    reg = <REG_CKG_FUART5_SYNTH_IN_BASE 0x4>;
    mux-shift = <6>;  //2+REG_CKG_FUART5_SYNTH_IN_OFFSET
    mux-width = <2>;
    gate-shift = <4>;  //0+REG_CKG_FUART5_SYNTH_IN_OFFSET
    auto-enable = <1>;
};

CLK_fuart6_synth_in: CLK_fuart6_synth_in {
    #clock-cells = <0>;
    compatible = "sstar,composite-clock";
    clocks = <&CLK_mpll_432m>,<&CLK_mpll_216m>,<&CLK_VOID>,<&CLK_VOID>;
    reg = <REG_CKG_FUART6_SYNTH_IN_BASE 0x4>;
    mux-shift = <6>;  //2+REG_CKG_FUART6_SYNTH_IN_OFFSET
    mux-width = <2>;
    gate-shift = <4>;  //0+REG_CKG_FUART6_SYNTH_IN_OFFSET
    auto-enable = <1>;
};

CLK_fuart7_synth_in: CLK_fuart7_synth_in {
    #clock-cells = <0>;
    compatible = "sstar,composite-clock";
    clocks = <&CLK_mpll_432m>,<&CLK_mpll_216m>,<&CLK_VOID>,<&CLK_VOID>;
    reg = <REG_CKG_FUART7_SYNTH_IN_BASE 0x4>;
    mux-shift = <6>;  //2+REG_CKG_FUART7_SYNTH_IN_OFFSET
    mux-width = <2>;
    gate-shift = <4>;  //0+REG_CKG_FUART7_SYNTH_IN_OFFSET
    auto-enable = <1>;
};

CLK_fuart: CLK_fuart {
    #clock-cells = <0>;
    compatible = "sstar,composite-clock";
    clocks = <&CLK_mpll_172m>,<&CLK_mpll_288m_div2>,<&CLK_xtali_24m>,<&CLK_fuart_synth_out>;
    reg = <REG_CKG_FUART_BASE 0x4>;
    mux-shift = <2>;  //2+REG_CKG_FUART_OFFSET
    mux-width = <2>;
    gate-shift = <0>;  //0+REG_CKG_FUART_OFFSET
    auto-enable = <1>;
};

CLK_fuart0: CLK_fuart0 {
    #clock-cells = <0>;
    compatible = "sstar,composite-clock";
    clocks = <&CLK_mpll_172m>,<&CLK_mpll_288m_div2>,<&CLK_xtali_24m>,<&CLK_fuart0_synth_out>;
    reg = <REG_CKG_FUART0_BASE 0x4>;
    mux-shift = <2>;  //2+REG_CKG_FUART0_OFFSET
    mux-width = <2>;
    gate-shift = <0>;  //0+REG_CKG_FUART0_OFFSET
    auto-enable = <1>;
};

CLK_fuart1: CLK_fuart1 {
    #clock-cells = <0>;
    compatible = "sstar,composite-clock";
    clocks = <&CLK_mpll_172m>,<&CLK_mpll_288m_div2>,<&CLK_xtali_24m>,<&CLK_fuart1_synth_out>;
    reg = <REG_CKG_FUART1_BASE 0x4>;
    mux-shift = <6>;  //2+REG_CKG_FUART1_OFFSET
    mux-width = <2>;
    gate-shift = <4>;  //0+REG_CKG_FUART1_OFFSET
    auto-enable = <1>;
};

CLK_fuart2: CLK_fuart2 {
    #clock-cells = <0>;
    compatible = "sstar,composite-clock";
    clocks = <&CLK_mpll_172m>,<&CLK_mpll_288m_div2>,<&CLK_xtali_24m>,<&CLK_fuart2_synth_out>;
    reg = <REG_CKG_FUART2_BASE 0x4>;
    mux-shift = <10>;  //2+REG_CKG_FUART2_OFFSET
    mux-width = <2>;
    gate-shift = <8>;  //0+REG_CKG_FUART2_OFFSET
    auto-enable = <1>;
};

CLK_fuart3: CLK_fuart3 {
    #clock-cells = <0>;
    compatible = "sstar,composite-clock";
    clocks = <&CLK_mpll_172m>,<&CLK_mpll_288m_div2>,<&CLK_xtali_24m>,<&CLK_fuart3_synth_out>;
    reg = <REG_CKG_FUART3_BASE 0x4>;
    mux-shift = <2>;  //2+REG_CKG_FUART3_OFFSET
    mux-width = <2>;
    gate-shift = <0>;  //0+REG_CKG_FUART3_OFFSET
    auto-enable = <1>;
};

CLK_fuart4: CLK_fuart4 {
    #clock-cells = <0>;
    compatible = "sstar,composite-clock";
    clocks = <&CLK_mpll_172m>,<&CLK_mpll_288m_div2>,<&CLK_xtali_24m>,<&CLK_fuart4_synth_out>;
    reg = <REG_CKG_FUART4_BASE 0x4>;
    mux-shift = <2>;  //2+REG_CKG_FUART4_OFFSET
    mux-width = <2>;
    gate-shift = <0>;  //0+REG_CKG_FUART4_OFFSET
    auto-enable = <1>;
};

CLK_fuart5: CLK_fuart5 {
    #clock-cells = <0>;
    compatible = "sstar,composite-clock";
    clocks = <&CLK_mpll_172m>,<&CLK_mpll_288m_div2>,<&CLK_xtali_24m>,<&CLK_fuart5_synth_out>;
    reg = <REG_CKG_FUART5_BASE 0x4>;
    mux-shift = <2>;  //2+REG_CKG_FUART5_OFFSET
    mux-width = <2>;
    gate-shift = <0>;  //0+REG_CKG_FUART5_OFFSET
    auto-enable = <1>;
};

CLK_fuart6: CLK_fuart6 {
    #clock-cells = <0>;
    compatible = "sstar,composite-clock";
    clocks = <&CLK_mpll_172m>,<&CLK_mpll_288m_div2>,<&CLK_xtali_24m>,<&CLK_fuart6_synth_out>;
    reg = <REG_CKG_FUART6_BASE 0x4>;
    mux-shift = <2>;  //2+REG_CKG_FUART6_OFFSET
    mux-width = <2>;
    gate-shift = <0>;  //0+REG_CKG_FUART6_OFFSET
    auto-enable = <1>;
};

CLK_fuart7: CLK_fuart7 {
    #clock-cells = <0>;
    compatible = "sstar,composite-clock";
    clocks = <&CLK_mpll_172m>,<&CLK_mpll_288m_div2>,<&CLK_xtali_24m>,<&CLK_fuart7_synth_out>;
    reg = <REG_CKG_FUART7_BASE 0x4>;
    mux-shift = <2>;  //2+REG_CKG_FUART7_OFFSET
    mux-width = <2>;
    gate-shift = <0>;  //0+REG_CKG_FUART7_OFFSET
    auto-enable = <1>;
};

CLK_mspi0: CLK_mspi0 {
    #clock-cells = <0>;
    compatible = "sstar,composite-clock";
    clocks = <&CLK_mpll_288m_div2>,<&CLK_mpll_432m_div8>,<&CLK_xtali_12m>,<&CLK_mpll_432m_div4>,<&CLK_spi_synth_pll>,<&CLK_mpll_288m_div4>,<&CLK_VOID>,<&CLK_VOID>;
    reg = <REG_CKG_MSPI0_BASE 0x4>;
    mux-shift = <2>;  //2+REG_CKG_MSPI0_OFFSET
    mux-width = <3>;
    gate-shift = <0>;  //0+REG_CKG_MSPI0_OFFSET
    auto-enable = <1>;
};

CLK_mspi1: CLK_mspi1 {
    #clock-cells = <0>;
    compatible = "sstar,composite-clock";
    clocks = <&CLK_mpll_288m_div2>,<&CLK_mpll_432m_div8>,<&CLK_xtali_12m>,<&CLK_mpll_432m_div4>,<&CLK_spi_synth_pll>,<&CLK_mpll_288m_div4>,<&CLK_VOID>,<&CLK_VOID>;
    reg = <REG_CKG_MSPI1_BASE 0x4>;
    mux-shift = <10>;  //2+REG_CKG_MSPI1_OFFSET
    mux-width = <3>;
    gate-shift = <8>;  //0+REG_CKG_MSPI1_OFFSET
    auto-enable = <1>;
};

CLK_mspi2: CLK_mspi2 {
    #clock-cells = <0>;
    compatible = "sstar,composite-clock";
    clocks = <&CLK_mpll_288m_div2>,<&CLK_mpll_432m_div8>,<&CLK_xtali_12m>,<&CLK_mpll_432m_div4>,<&CLK_spi_synth_pll>,<&CLK_mpll_288m_div4>,<&CLK_VOID>,<&CLK_VOID>;
    reg = <REG_CKG_MSPI2_BASE 0x4>;
    mux-shift = <10>;  //2+REG_CKG_MSPI2_OFFSET
    mux-width = <3>;
    gate-shift = <8>;  //0+REG_CKG_MSPI2_OFFSET
    auto-enable = <1>;
};

CLK_mspi3: CLK_mspi3 {
    #clock-cells = <0>;
    compatible = "sstar,composite-clock";
    clocks = <&CLK_mpll_288m_div2>,<&CLK_mpll_432m_div8>,<&CLK_xtali_12m>,<&CLK_mpll_432m_div4>,<&CLK_spi_synth_pll>,<&CLK_mpll_288m_div4>,<&CLK_VOID>,<&CLK_VOID>;
    reg = <REG_CKG_MSPI3_BASE 0x4>;
    mux-shift = <2>;  //2+REG_CKG_MSPI3_OFFSET
    mux-width = <3>;
    gate-shift = <0>;  //0+REG_CKG_MSPI3_OFFSET
    auto-enable = <1>;
};

CLK_miic0: CLK_miic0 {
    #clock-cells = <0>;
    compatible = "sstar,composite-clock";
    clocks = <&CLK_mpll_288m_div4>,<&CLK_mpll_432m_div8>,<&CLK_xtali_12m>,<&CLK_VOID>;
    reg = <REG_CKG_MIIC0_BASE 0x4>;
    mux-shift = <2>;  //2+REG_CKG_MIIC0_OFFSET
    mux-width = <2>;
    gate-shift = <0>;  //0+REG_CKG_MIIC0_OFFSET
    auto-enable = <1>;
};

CLK_miic1: CLK_miic1 {
    #clock-cells = <0>;
    compatible = "sstar,composite-clock";
    clocks = <&CLK_mpll_288m_div4>,<&CLK_mpll_432m_div8>,<&CLK_xtali_12m>,<&CLK_VOID>;
    reg = <REG_CKG_MIIC1_BASE 0x4>;
    mux-shift = <10>;  //2+REG_CKG_MIIC1_OFFSET
    mux-width = <2>;
    gate-shift = <8>;  //0+REG_CKG_MIIC1_OFFSET
    auto-enable = <1>;
};

CLK_miic2: CLK_miic2 {
    #clock-cells = <0>;
    compatible = "sstar,composite-clock";
    clocks = <&CLK_mpll_288m_div4>,<&CLK_mpll_432m_div8>,<&CLK_xtali_12m>,<&CLK_VOID>;
    reg = <REG_CKG_MIIC2_BASE 0x4>;
    mux-shift = <14>;  //2+REG_CKG_MIIC2_OFFSET
    mux-width = <2>;
    gate-shift = <12>;  //0+REG_CKG_MIIC2_OFFSET
    auto-enable = <1>;
};

CLK_miic3: CLK_miic3 {
    #clock-cells = <0>;
    compatible = "sstar,composite-clock";
    clocks = <&CLK_mpll_288m_div4>,<&CLK_mpll_432m_div8>,<&CLK_xtali_12m>,<&CLK_VOID>;
    reg = <REG_CKG_MIIC3_BASE 0x4>;
    mux-shift = <2>;  //2+REG_CKG_MIIC3_OFFSET
    mux-width = <2>;
    gate-shift = <0>;  //0+REG_CKG_MIIC3_OFFSET
    auto-enable = <1>;
};

CLK_miic4: CLK_miic4 {
    #clock-cells = <0>;
    compatible = "sstar,composite-clock";
    clocks = <&CLK_mpll_288m_div4>,<&CLK_mpll_432m_div8>,<&CLK_xtali_12m>,<&CLK_VOID>;
    reg = <REG_CKG_MIIC4_BASE 0x4>;
    mux-shift = <10>;  //2+REG_CKG_MIIC4_OFFSET
    mux-width = <2>;
    gate-shift = <8>;  //0+REG_CKG_MIIC4_OFFSET
    auto-enable = <1>;
};

CLK_miic5: CLK_miic5 {
    #clock-cells = <0>;
    compatible = "sstar,composite-clock";
    clocks = <&CLK_mpll_288m_div4>,<&CLK_mpll_432m_div8>,<&CLK_xtali_12m>,<&CLK_VOID>;
    reg = <REG_CKG_MIIC5_BASE 0x4>;
    mux-shift = <14>;  //2+REG_CKG_MIIC5_OFFSET
    mux-width = <2>;
    gate-shift = <12>;  //0+REG_CKG_MIIC5_OFFSET
    auto-enable = <1>;
};

/* CLK_bist: CLK_bist {
    #clock-cells = <0>;
    compatible = "sstar,composite-clock";
    clocks = <&CLK_upll_320m>,<&CLK_mpll_288m>,<&CLK_upll_480m_div2>,<&CLK_mpll_216m>,<&CLK_mpll_172m>,<&CLK_mpll_288m_div2>,<&CLK_mpll_432m_div8>,<&CLK_xtali_12m>;
    reg = <REG_CKG_BIST_BASE 0x4>;
    mux-shift = <2>;  //2+REG_CKG_BIST_OFFSET
    mux-width = <3>;
    gate-shift = <0>;  //0+REG_CKG_BIST_OFFSET
    auto-enable = <1>;
}; */

/* CLK_bist_mcu: CLK_bist_mcu {
    #clock-cells = <0>;
    compatible = "sstar,composite-clock";
    clocks = <&CLK_upll_320m>,<&CLK_mpll_288m>,<&CLK_upll_480m_div2>,<&CLK_mpll_216m>,<&CLK_mpll_172m>,<&CLK_mpll_288m_div2>,<&CLK_mpll_432m_div8>,<&CLK_xtali_12m>;
    reg = <REG_CKG_BIST_MCU_BASE 0x4>;
    mux-shift = <2>;  //2+REG_CKG_BIST_MCU_OFFSET
    mux-width = <3>;
    gate-shift = <0>;  //0+REG_CKG_BIST_MCU_OFFSET
    auto-enable = <1>;
}; */

/* CLK_pwr_ctl: CLK_pwr_ctl {
    #clock-cells = <0>;
    compatible = "sstar,composite-clock";
    clocks = <&CLK_xtali_12m_div16>,<&CLK_xtali_12m_div8>,<&CLK_xtali_12m>,<&CLK_VOID>;
    reg = <REG_CKG_PWR_CTL_BASE 0x4>;
    mux-shift = <2>;  //2+REG_CKG_PWR_CTL_OFFSET
    mux-width = <2>;
    gate-shift = <0>;  //0+REG_CKG_PWR_CTL_OFFSET
    auto-enable = <1>;
}; */

/* CLK_xtali: CLK_xtali {
    #clock-cells = <0>;
    compatible = "sstar,composite-clock";
    clocks = <&CLK_xtali_12m>,<&CLK_VOID>,<&CLK_VOID>,<&CLK_VOID>;
    reg = <REG_CKG_XTALI_BASE 0x4>;
    mux-shift = <2>;  //2+REG_CKG_XTALI_OFFSET
    mux-width = <2>;
    gate-shift = <0>;  //0+REG_CKG_XTALI_OFFSET
    auto-enable = <1>;
}; */

CLK_xtali_24: CLK_xtali_24 {
    #clock-cells = <0>;
    compatible = "sstar,composite-clock";
    clocks = <&CLK_xtali_24m>,<&CLK_VOID>,<&CLK_VOID>,<&CLK_VOID>;
    reg = <REG_CKG_XTALI_24_BASE 0x4>;
    mux-shift = <14>;  //2+REG_CKG_XTALI_24_OFFSET
    mux-width = <2>;
    gate-shift = <12>;  //0+REG_CKG_XTALI_24_OFFSET
    auto-enable = <1>;
};

/* CLK_live_c: CLK_live_c {
    #clock-cells = <0>;
    compatible = "sstar,composite-clock";
    clocks = <&CLK_xtali_12m>,<&CLK_VOID>,<&CLK_VOID>,<&CLK_VOID>;
    reg = <REG_CKG_LIVE_BASE 0x4>;
    mux-shift = <10>;  //2+REG_CKG_LIVE_OFFSET
    mux-width = <2>;
    gate-shift = <8>;  //0+REG_CKG_LIVE_OFFSET
    auto-enable = <1>;
}; */

/* CLK_live: CLK_live {
    #clock-cells = <0>;
    compatible = "sstar,composite-clock";
    clocks = <&CLK_xtali_12m>,<&CLK_VOID>,<&CLK_VOID>,<&CLK_VOID>;
    reg = <REG_CKG_LIVE_BASE 0x4>;
    mux-shift = <10>;  //2+REG_CKG_LIVE_OFFSET
    mux-width = <2>;
    gate-shift = <8>;  //0+REG_CKG_LIVE_OFFSET
    auto-enable = <1>;
}; */

CLK_real_live: CLK_real_live {
    #clock-cells = <0>;
    compatible = "sstar,composite-clock";
    clocks = <&CLK_xtali_12m_v_live>,<&CLK_VOID>,<&CLK_VOID>,<&CLK_VOID>;
    reg = <REG_CKG_REAL_LIVE_BASE 0x4>;
    mux-shift = <2>;  //2+REG_CKG_REAL_LIVE_OFFSET
    mux-width = <2>;
    gate-shift = <0>;  //0+REG_CKG_REAL_LIVE_OFFSET
    auto-enable = <1>;
};

/* CLK_sr00_mclk: CLK_sr00_mclk {
    #clock-cells = <0>;
    compatible = "sstar,composite-clock";
    clocks = <&CLK_mpll_432m_div16>,<&CLK_mpll_288m_div4>,<&CLK_mpll_123m_div2>,<&CLK_mpll_432m_div8>,<&CLK_upll_384m_div8>,<&CLK_mpll_86m_div2>,<&CLK_mpll_288m_div8>,<&CLK_xtali_24m>,<&CLK_mpll_86m_div4>,<&CLK_xtali_12m>,<&CLK_mpll_86m_div16>,<&CLK_isppll_clk_div2>,<&CLK_isppll_clk_div4>,<&CLK_isppll_clk_div8>,<&CLK_isppll_clk_div16>,<&CLK_VOID>;
    reg = <REG_CKG_SR00_MCLK_BASE 0x4>;
    mux-shift = <10>;  //2+REG_CKG_SR00_MCLK_OFFSET
    mux-width = <4>;
    gate-shift = <8>;  //0+REG_CKG_SR00_MCLK_OFFSET
    auto-enable = <1>;
}; */

/* CLK_sr01_mclk: CLK_sr01_mclk {
    #clock-cells = <0>;
    compatible = "sstar,composite-clock";
    clocks = <&CLK_mpll_432m_div16>,<&CLK_mpll_288m_div4>,<&CLK_mpll_123m_div2>,<&CLK_mpll_432m_div8>,<&CLK_upll_384m_div8>,<&CLK_mpll_86m_div2>,<&CLK_mpll_288m_div8>,<&CLK_xtali_24m>,<&CLK_mpll_86m_div4>,<&CLK_xtali_12m>,<&CLK_mpll_86m_div16>,<&CLK_isppll_clk_div2>,<&CLK_isppll_clk_div4>,<&CLK_isppll_clk_div8>,<&CLK_isppll_clk_div16>,<&CLK_VOID>;
    reg = <REG_CKG_SR01_MCLK_BASE 0x4>;
    mux-shift = <2>;  //2+REG_CKG_SR01_MCLK_OFFSET
    mux-width = <4>;
    gate-shift = <0>;  //0+REG_CKG_SR01_MCLK_OFFSET
    auto-enable = <1>;
}; */

/* CLK_sr02_mclk: CLK_sr02_mclk {
    #clock-cells = <0>;
    compatible = "sstar,composite-clock";
    clocks = <&CLK_mpll_432m_div16>,<&CLK_mpll_288m_div4>,<&CLK_mpll_123m_div2>,<&CLK_mpll_432m_div8>,<&CLK_upll_384m_div8>,<&CLK_mpll_86m_div2>,<&CLK_mpll_288m_div8>,<&CLK_xtali_24m>,<&CLK_mpll_86m_div4>,<&CLK_xtali_12m>,<&CLK_mpll_86m_div16>,<&CLK_isppll_clk_div2>,<&CLK_isppll_clk_div4>,<&CLK_isppll_clk_div8>,<&CLK_isppll_clk_div16>,<&CLK_VOID>;
    reg = <REG_CKG_SR02_MCLK_BASE 0x4>;
    mux-shift = <10>;  //2+REG_CKG_SR02_MCLK_OFFSET
    mux-width = <4>;
    gate-shift = <8>;  //0+REG_CKG_SR02_MCLK_OFFSET
    auto-enable = <1>;
}; */

/* CLK_sr03_mclk: CLK_sr03_mclk {
    #clock-cells = <0>;
    compatible = "sstar,composite-clock";
    clocks = <&CLK_mpll_432m_div16>,<&CLK_mpll_288m_div4>,<&CLK_mpll_123m_div2>,<&CLK_mpll_432m_div8>,<&CLK_upll_384m_div8>,<&CLK_mpll_86m_div2>,<&CLK_mpll_288m_div8>,<&CLK_xtali_24m>,<&CLK_mpll_86m_div4>,<&CLK_xtali_12m>,<&CLK_mpll_86m_div16>,<&CLK_isppll_clk_div2>,<&CLK_isppll_clk_div4>,<&CLK_isppll_clk_div8>,<&CLK_isppll_clk_div16>,<&CLK_VOID>;
    reg = <REG_CKG_SR03_MCLK_BASE 0x4>;
    mux-shift = <10>;  //2+REG_CKG_SR03_MCLK_OFFSET
    mux-width = <4>;
    gate-shift = <8>;  //0+REG_CKG_SR03_MCLK_OFFSET
    auto-enable = <1>;
}; */

/* CLK_sr10_mclk: CLK_sr10_mclk {
    #clock-cells = <0>;
    compatible = "sstar,composite-clock";
    clocks = <&CLK_mpll_432m_div16>,<&CLK_mpll_288m_div4>,<&CLK_mpll_123m_div2>,<&CLK_mpll_432m_div8>,<&CLK_upll_384m_div8>,<&CLK_mpll_86m_div2>,<&CLK_mpll_288m_div8>,<&CLK_xtali_24m>,<&CLK_mpll_86m_div4>,<&CLK_xtali_12m>,<&CLK_mpll_86m_div16>,<&CLK_isppll_clk_div2>,<&CLK_isppll_clk_div4>,<&CLK_isppll_clk_div8>,<&CLK_isppll_clk_div16>,<&CLK_VOID>;
    reg = <REG_CKG_SR10_MCLK_BASE 0x4>;
    mux-shift = <2>;  //2+REG_CKG_SR10_MCLK_OFFSET
    mux-width = <4>;
    gate-shift = <0>;  //0+REG_CKG_SR10_MCLK_OFFSET
    auto-enable = <1>;
}; */

/* CLK_sr11_mclk: CLK_sr11_mclk {
    #clock-cells = <0>;
    compatible = "sstar,composite-clock";
    clocks = <&CLK_mpll_432m_div16>,<&CLK_mpll_288m_div4>,<&CLK_mpll_123m_div2>,<&CLK_mpll_432m_div8>,<&CLK_upll_384m_div8>,<&CLK_mpll_86m_div2>,<&CLK_mpll_288m_div8>,<&CLK_xtali_24m>,<&CLK_mpll_86m_div4>,<&CLK_xtali_12m>,<&CLK_mpll_86m_div16>,<&CLK_isppll_clk_div2>,<&CLK_isppll_clk_div4>,<&CLK_isppll_clk_div8>,<&CLK_isppll_clk_div16>,<&CLK_VOID>;
    reg = <REG_CKG_SR11_MCLK_BASE 0x4>;
    mux-shift = <10>;  //2+REG_CKG_SR11_MCLK_OFFSET
    mux-width = <4>;
    gate-shift = <8>;  //0+REG_CKG_SR11_MCLK_OFFSET
    auto-enable = <1>;
}; */

/* CLK_sr12_mclk: CLK_sr12_mclk {
    #clock-cells = <0>;
    compatible = "sstar,composite-clock";
    clocks = <&CLK_mpll_432m_div16>,<&CLK_mpll_288m_div4>,<&CLK_mpll_123m_div2>,<&CLK_mpll_432m_div8>,<&CLK_upll_384m_div8>,<&CLK_mpll_86m_div2>,<&CLK_mpll_288m_div8>,<&CLK_xtali_24m>,<&CLK_mpll_86m_div4>,<&CLK_xtali_12m>,<&CLK_mpll_86m_div16>,<&CLK_isppll_clk_div2>,<&CLK_isppll_clk_div4>,<&CLK_isppll_clk_div8>,<&CLK_isppll_clk_div16>,<&CLK_VOID>;
    reg = <REG_CKG_SR12_MCLK_BASE 0x4>;
    mux-shift = <2>;  //2+REG_CKG_SR12_MCLK_OFFSET
    mux-width = <4>;
    gate-shift = <0>;  //0+REG_CKG_SR12_MCLK_OFFSET
    auto-enable = <1>;
}; */

/* CLK_sr13_mclk: CLK_sr13_mclk {
    #clock-cells = <0>;
    compatible = "sstar,composite-clock";
    clocks = <&CLK_mpll_432m_div16>,<&CLK_mpll_288m_div4>,<&CLK_mpll_123m_div2>,<&CLK_mpll_432m_div8>,<&CLK_upll_384m_div8>,<&CLK_mpll_86m_div2>,<&CLK_mpll_288m_div8>,<&CLK_xtali_24m>,<&CLK_mpll_86m_div4>,<&CLK_xtali_12m>,<&CLK_mpll_86m_div16>,<&CLK_isppll_clk_div2>,<&CLK_isppll_clk_div4>,<&CLK_isppll_clk_div8>,<&CLK_isppll_clk_div16>,<&CLK_VOID>;
    reg = <REG_CKG_SR13_MCLK_BASE 0x4>;
    mux-shift = <10>;  //2+REG_CKG_SR13_MCLK_OFFSET
    mux-width = <4>;
    gate-shift = <8>;  //0+REG_CKG_SR13_MCLK_OFFSET
    auto-enable = <1>;
}; */

/* CLK_nuc: CLK_nuc {
    #clock-cells = <0>;
    compatible = "sstar,composite-clock";
    clocks = <&CLK_mpll_432m_div16>,<&CLK_mpll_288m_div4>,<&CLK_mpll_123m_div2>,<&CLK_mpll_432m_div8>,<&CLK_upll_384m_div8>,<&CLK_mpll_86m_div2>,<&CLK_mpll_288m_div8>,<&CLK_xtali_24m>,<&CLK_mpll_86m_div4>,<&CLK_xtali_12m>,<&CLK_mpll_86m_div16>,<&CLK_isppll_clk_div2>,<&CLK_isppll_clk_div4>,<&CLK_isppll_clk_div8>,<&CLK_isppll_clk_div16>,<&CLK_VOID>;
    reg = <REG_CKG_NUC_BASE 0x4>;
    mux-shift = <10>;  //2+REG_CKG_NUC_OFFSET
    mux-width = <4>;
    gate-shift = <8>;  //0+REG_CKG_NUC_OFFSET
    auto-enable = <1>;
}; */

/* CLK_ssm0: CLK_ssm0 {
    #clock-cells = <0>;
    compatible = "sstar,composite-clock";
    clocks = <&CLK_mpll_432m_div16>,<&CLK_mpll_288m_div4>,<&CLK_mpll_123m_div2>,<&CLK_mpll_432m_div8>,<&CLK_upll_384m_div8>,<&CLK_mpll_86m_div2>,<&CLK_mpll_288m_div8>,<&CLK_xtali_24m>,<&CLK_mpll_86m_div4>,<&CLK_xtali_12m>,<&CLK_mpll_86m_div16>,<&CLK_isppll_clk_div2>,<&CLK_isppll_clk_div4>,<&CLK_isppll_clk_div8>,<&CLK_isppll_clk_div16>,<&CLK_VOID>;
    reg = <REG_CKG_SSM0_BASE 0x4>;
    mux-shift = <2>;  //2+REG_CKG_SSM0_OFFSET
    mux-width = <4>;
    gate-shift = <0>;  //0+REG_CKG_SSM0_OFFSET
    auto-enable = <1>;
}; */

/* CLK_ssm1: CLK_ssm1 {
    #clock-cells = <0>;
    compatible = "sstar,composite-clock";
    clocks = <&CLK_mpll_432m_div16>,<&CLK_mpll_288m_div4>,<&CLK_mpll_123m_div2>,<&CLK_mpll_432m_div8>,<&CLK_upll_384m_div8>,<&CLK_mpll_86m_div2>,<&CLK_mpll_288m_div8>,<&CLK_xtali_24m>,<&CLK_mpll_86m_div4>,<&CLK_xtali_12m>,<&CLK_mpll_86m_div16>,<&CLK_isppll_clk_div2>,<&CLK_isppll_clk_div4>,<&CLK_isppll_clk_div8>,<&CLK_isppll_clk_div16>,<&CLK_VOID>;
    reg = <REG_CKG_SSM1_BASE 0x4>;
    mux-shift = <10>;  //2+REG_CKG_SSM1_OFFSET
    mux-width = <4>;
    gate-shift = <8>;  //0+REG_CKG_SSM1_OFFSET
    auto-enable = <1>;
}; */

/* CLK_bist_ipu_gp: CLK_bist_ipu_gp {
    #clock-cells = <0>;
    compatible = "sstar,composite-clock";
    clocks = <&CLK_upll_320m>,<&CLK_mpll_288m>,<&CLK_upll_480m_div2>,<&CLK_mpll_216m>,<&CLK_mpll_172m>,<&CLK_mpll_288m_div2>,<&CLK_mpll_432m_div8>,<&CLK_xtali_12m>;
    reg = <REG_CKG_BIST_IPU_GP_BASE 0x4>;
    mux-shift = <2>;  //2+REG_CKG_BIST_IPU_GP_OFFSET
    mux-width = <3>;
    gate-shift = <0>;  //0+REG_CKG_BIST_IPU_GP_OFFSET
    auto-enable = <1>;
}; */

CLK_ipu: CLK_ipu {
    #clock-cells = <0>;
    compatible = "sstar,composite-clock";
    clocks = <&CLK_xtali_12m>,<&CLK_mpll_288m_div4>,<&CLK_mpll_172m>,<&CLK_mpll_288m>,<&CLK_upll_320m>,<&CLK_upll_384m>,<&CLK_mpll_432m>,<&CLK_upll_480m>;
    reg = <REG_CKG_IPU_BASE 0x4>;
    mux-shift = <2>;  //2+REG_CKG_IPU_OFFSET
    mux-width = <3>;
    gate-shift = <0>;  //0+REG_CKG_IPU_OFFSET
    auto-enable = <1>;
};

CLK_ipuff: CLK_ipuff {
    #clock-cells = <0>;
    compatible = "sstar,composite-clock";
    clocks = <&CLK_mpll_432m>,<&CLK_upll_384m>,<&CLK_upll_320m>,<&CLK_upll_480m_div2>;
    reg = <REG_CKG_IPUFF_BASE 0x4>;
    mux-shift = <10>;  //2+REG_CKG_IPUFF_OFFSET
    mux-width = <2>;
    gate-shift = <8>;  //0+REG_CKG_IPUFF_OFFSET
    auto-enable = <1>;
};

CLK_bist_usb30_drd_gp: CLK_bist_usb30_drd_gp {
    #clock-cells = <0>;
    compatible = "sstar,composite-clock";
    clocks = <&CLK_upll_320m>,<&CLK_mpll_288m>,<&CLK_upll_480m_div2>,<&CLK_mpll_216m>,<&CLK_mpll_172m>,<&CLK_mpll_288m_div2>,<&CLK_mpll_432m_div8>,<&CLK_xtali_12m>;
    reg = <REG_CKG_BIST_USB30_DRD_GP_BASE 0x4>;
    mux-shift = <10>;  //2+REG_CKG_BIST_USB30_DRD_GP_OFFSET
    mux-width = <3>;
    gate-shift = <8>;  //0+REG_CKG_BIST_USB30_DRD_GP_OFFSET
    auto-enable = <1>;
};

CLK_sof_usb30_drd: CLK_sof_usb30_drd {
    #clock-cells = <0>;
    compatible = "sstar,composite-clock";
    clocks = <&CLK_xtali_24m>,<&CLK_upll_384m_div8>,<&CLK_mpll_432m_div8>,<&CLK_mpll_432m_div4>;
    reg = <REG_CKG_SOF_USB30_DRD_BASE 0x4>;
    mux-shift = <10>;  //2+REG_CKG_SOF_USB30_DRD_OFFSET
    mux-width = <2>;
    gate-shift = <8>;  //0+REG_CKG_SOF_USB30_DRD_OFFSET
    auto-enable = <1>;
};

CLK_ssusb_axi: CLK_ssusb_axi {
    #clock-cells = <0>;
    compatible = "sstar,composite-clock";
    clocks = <&CLK_mpll_288m>,<&CLK_mpll_216m>,<&CLK_mpll_172m>,<&CLK_mpll_432m_div4>;
    reg = <REG_CKG_SSUSB_AXI_BASE 0x4>;
    mux-shift = <14>;  //2+REG_CKG_SSUSB_AXI_OFFSET
    mux-width = <2>;
    gate-shift = <12>;  //0+REG_CKG_SSUSB_AXI_OFFSET
    auto-enable = <1>;
};

CLK_ssusb_phy_108: CLK_ssusb_phy_108 {
    #clock-cells = <0>;
    compatible = "sstar,composite-clock";
    clocks = <&CLK_mpll_432m_div4>,<&CLK_VOID>,<&CLK_VOID>,<&CLK_VOID>;
    reg = <REG_CKG_SSUSB_PHY_108_BASE 0x4>;
    mux-shift = <2>;  //2+REG_CKG_SSUSB_PHY_108_OFFSET
    mux-width = <2>;
    gate-shift = <0>;  //0+REG_CKG_SSUSB_PHY_108_OFFSET
    auto-enable = <1>;
};

CLK_ssusb_phy_432: CLK_ssusb_phy_432 {
    #clock-cells = <0>;
    compatible = "sstar,composite-clock";
    clocks = <&CLK_mpll_432m>,<&CLK_VOID>,<&CLK_VOID>,<&CLK_VOID>;
    reg = <REG_CKG_SSUSB_PHY_432_BASE 0x4>;
    mux-shift = <6>;  //2+REG_CKG_SSUSB_PHY_432_OFFSET
    mux-width = <2>;
    gate-shift = <4>;  //0+REG_CKG_SSUSB_PHY_432_OFFSET
    auto-enable = <1>;
};

CLK_csi_mac_lptx_top_i_0: CLK_csi_mac_lptx_top_i_0 {
    #clock-cells = <0>;
    compatible = "sstar,composite-clock";
    clocks = <&CLK_mpll_432m>,<&CLK_upll_384m>,<&CLK_upll_320m>,<&CLK_mpll_288m>,<&CLK_upll_480m_div2>,<&CLK_mpll_216m>,<&CLK_mpll_172m>,<&CLK_upll_480m>;
    reg = <REG_CKG_CSI_MAC_LPTX_TOP_I_0_BASE 0x4>;
    mux-shift = <2>;  //2+REG_CKG_CSI_MAC_LPTX_TOP_I_0_OFFSET
    mux-width = <3>;
    gate-shift = <0>;  //0+REG_CKG_CSI_MAC_LPTX_TOP_I_0_OFFSET
    auto-enable = <1>;
};

CLK_csi_mac_top_i_0: CLK_csi_mac_top_i_0 {
    #clock-cells = <0>;
    compatible = "sstar,composite-clock";
    clocks = <&CLK_mpll_432m>,<&CLK_upll_384m>,<&CLK_upll_320m>,<&CLK_mpll_288m>,<&CLK_upll_480m_div2>,<&CLK_mpll_216m>,<&CLK_mpll_172m>,<&CLK_upll_480m>;
    reg = <REG_CKG_CSI_MAC_TOP_I_0_BASE 0x4>;
    mux-shift = <10>;  //2+REG_CKG_CSI_MAC_TOP_I_0_OFFSET
    mux-width = <3>;
    gate-shift = <8>;  //0+REG_CKG_CSI_MAC_TOP_I_0_OFFSET
    auto-enable = <1>;
};

CLK_ns_top_i_0: CLK_ns_top_i_0 {
    #clock-cells = <0>;
    compatible = "sstar,composite-clock";
    clocks = <&CLK_mpll_432m>,<&CLK_upll_384m>,<&CLK_upll_320m>,<&CLK_mpll_288m>,<&CLK_upll_480m_div2>,<&CLK_mpll_216m>,<&CLK_mpll_172m>,<&CLK_upll_480m>;
    reg = <REG_CKG_NS_TOP_I_0_BASE 0x4>;
    mux-shift = <2>;  //2+REG_CKG_NS_TOP_I_0_OFFSET
    mux-width = <3>;
    gate-shift = <0>;  //0+REG_CKG_NS_TOP_I_0_OFFSET
    auto-enable = <1>;
};

CLK_csi_mac_lptx_top_i_1: CLK_csi_mac_lptx_top_i_1 {
    #clock-cells = <0>;
    compatible = "sstar,composite-clock";
    clocks = <&CLK_mpll_432m>,<&CLK_upll_384m>,<&CLK_upll_320m>,<&CLK_mpll_288m>,<&CLK_upll_480m_div2>,<&CLK_mpll_216m>,<&CLK_mpll_172m>,<&CLK_upll_480m>;
    reg = <REG_CKG_CSI_MAC_LPTX_TOP_I_1_BASE 0x4>;
    mux-shift = <10>;  //2+REG_CKG_CSI_MAC_LPTX_TOP_I_1_OFFSET
    mux-width = <3>;
    gate-shift = <8>;  //0+REG_CKG_CSI_MAC_LPTX_TOP_I_1_OFFSET
    auto-enable = <1>;
};

CLK_csi_mac_top_i_1: CLK_csi_mac_top_i_1 {
    #clock-cells = <0>;
    compatible = "sstar,composite-clock";
    clocks = <&CLK_mpll_432m>,<&CLK_upll_384m>,<&CLK_upll_320m>,<&CLK_mpll_288m>,<&CLK_upll_480m_div2>,<&CLK_mpll_216m>,<&CLK_mpll_172m>,<&CLK_upll_480m>;
    reg = <REG_CKG_CSI_MAC_TOP_I_1_BASE 0x4>;
    mux-shift = <2>;  //2+REG_CKG_CSI_MAC_TOP_I_1_OFFSET
    mux-width = <3>;
    gate-shift = <0>;  //0+REG_CKG_CSI_MAC_TOP_I_1_OFFSET
    auto-enable = <1>;
};

CLK_ns_top_i_1: CLK_ns_top_i_1 {
    #clock-cells = <0>;
    compatible = "sstar,composite-clock";
    clocks = <&CLK_mpll_432m>,<&CLK_upll_384m>,<&CLK_upll_320m>,<&CLK_mpll_288m>,<&CLK_upll_480m_div2>,<&CLK_mpll_216m>,<&CLK_mpll_172m>,<&CLK_upll_480m>;
    reg = <REG_CKG_NS_TOP_I_1_BASE 0x4>;
    mux-shift = <10>;  //2+REG_CKG_NS_TOP_I_1_OFFSET
    mux-width = <3>;
    gate-shift = <8>;  //0+REG_CKG_NS_TOP_I_1_OFFSET
    auto-enable = <1>;
};

CLK_csi_mac_lptx_top_i_2: CLK_csi_mac_lptx_top_i_2 {
    #clock-cells = <0>;
    compatible = "sstar,composite-clock";
    clocks = <&CLK_mpll_432m>,<&CLK_upll_384m>,<&CLK_upll_320m>,<&CLK_mpll_288m>,<&CLK_upll_480m_div2>,<&CLK_mpll_216m>,<&CLK_mpll_172m>,<&CLK_upll_480m>;
    reg = <REG_CKG_CSI_MAC_LPTX_TOP_I_2_BASE 0x4>;
    mux-shift = <2>;  //2+REG_CKG_CSI_MAC_LPTX_TOP_I_2_OFFSET
    mux-width = <3>;
    gate-shift = <0>;  //0+REG_CKG_CSI_MAC_LPTX_TOP_I_2_OFFSET
    auto-enable = <1>;
};

CLK_csi_mac_top_i_2: CLK_csi_mac_top_i_2 {
    #clock-cells = <0>;
    compatible = "sstar,composite-clock";
    clocks = <&CLK_mpll_432m>,<&CLK_upll_384m>,<&CLK_upll_320m>,<&CLK_mpll_288m>,<&CLK_upll_480m_div2>,<&CLK_mpll_216m>,<&CLK_mpll_172m>,<&CLK_upll_480m>;
    reg = <REG_CKG_CSI_MAC_TOP_I_2_BASE 0x4>;
    mux-shift = <10>;  //2+REG_CKG_CSI_MAC_TOP_I_2_OFFSET
    mux-width = <3>;
    gate-shift = <8>;  //0+REG_CKG_CSI_MAC_TOP_I_2_OFFSET
    auto-enable = <1>;
};

CLK_ns_top_i_2: CLK_ns_top_i_2 {
    #clock-cells = <0>;
    compatible = "sstar,composite-clock";
    clocks = <&CLK_mpll_432m>,<&CLK_upll_384m>,<&CLK_upll_320m>,<&CLK_mpll_288m>,<&CLK_upll_480m_div2>,<&CLK_mpll_216m>,<&CLK_mpll_172m>,<&CLK_upll_480m>;
    reg = <REG_CKG_NS_TOP_I_2_BASE 0x4>;
    mux-shift = <2>;  //2+REG_CKG_NS_TOP_I_2_OFFSET
    mux-width = <3>;
    gate-shift = <0>;  //0+REG_CKG_NS_TOP_I_2_OFFSET
    auto-enable = <1>;
};

CLK_csi_mac_lptx_top_i_3: CLK_csi_mac_lptx_top_i_3 {
    #clock-cells = <0>;
    compatible = "sstar,composite-clock";
    clocks = <&CLK_mpll_432m>,<&CLK_upll_384m>,<&CLK_upll_320m>,<&CLK_mpll_288m>,<&CLK_upll_480m_div2>,<&CLK_mpll_216m>,<&CLK_mpll_172m>,<&CLK_upll_480m>;
    reg = <REG_CKG_CSI_MAC_LPTX_TOP_I_3_BASE 0x4>;
    mux-shift = <2>;  //2+REG_CKG_CSI_MAC_LPTX_TOP_I_3_OFFSET
    mux-width = <3>;
    gate-shift = <0>;  //0+REG_CKG_CSI_MAC_LPTX_TOP_I_3_OFFSET
    auto-enable = <1>;
};

CLK_csi_mac_top_i_3: CLK_csi_mac_top_i_3 {
    #clock-cells = <0>;
    compatible = "sstar,composite-clock";
    clocks = <&CLK_mpll_432m>,<&CLK_upll_384m>,<&CLK_upll_320m>,<&CLK_mpll_288m>,<&CLK_upll_480m_div2>,<&CLK_mpll_216m>,<&CLK_mpll_172m>,<&CLK_upll_480m>;
    reg = <REG_CKG_CSI_MAC_TOP_I_3_BASE 0x4>;
    mux-shift = <10>;  //2+REG_CKG_CSI_MAC_TOP_I_3_OFFSET
    mux-width = <3>;
    gate-shift = <8>;  //0+REG_CKG_CSI_MAC_TOP_I_3_OFFSET
    auto-enable = <1>;
};

CLK_ns_top_i_3: CLK_ns_top_i_3 {
    #clock-cells = <0>;
    compatible = "sstar,composite-clock";
    clocks = <&CLK_mpll_432m>,<&CLK_upll_384m>,<&CLK_upll_320m>,<&CLK_mpll_288m>,<&CLK_upll_480m_div2>,<&CLK_mpll_216m>,<&CLK_mpll_172m>,<&CLK_upll_480m>;
    reg = <REG_CKG_NS_TOP_I_3_BASE 0x4>;
    mux-shift = <2>;  //2+REG_CKG_NS_TOP_I_3_OFFSET
    mux-width = <3>;
    gate-shift = <0>;  //0+REG_CKG_NS_TOP_I_3_OFFSET
    auto-enable = <1>;
};

CLK_mipi_tx_dsi0: CLK_mipi_tx_dsi0 {
    #clock-cells = <0>;
    compatible = "sstar,composite-clock";
    clocks = <&CLK_disppll_clk>,<&CLK_upll_320m_div2>,<&CLK_mpll_288m_div2>,<&CLK_mpll_216m>,<&CLK_upll_480m_div2>,<&CLK_mpll_432m_div4>,<&CLK_upll_320m>,<&CLK_VOID>;
    reg = <REG_CKG_MIPI_TX_DSI0_BASE 0x4>;
    mux-shift = <2>;  //2+REG_CKG_MIPI_TX_DSI0_OFFSET
    mux-width = <3>;
    gate-shift = <0>;  //0+REG_CKG_MIPI_TX_DSI0_OFFSET
    auto-enable = <1>;
};

CLK_bist_vhe_gp: CLK_bist_vhe_gp {
    #clock-cells = <0>;
    compatible = "sstar,composite-clock";
    clocks = <&CLK_upll_320m>,<&CLK_mpll_288m>,<&CLK_upll_480m_div2>,<&CLK_mpll_216m>,<&CLK_mpll_172m>,<&CLK_mpll_288m_div2>,<&CLK_mpll_432m_div8>,<&CLK_xtali_12m>;
    reg = <REG_CKG_BIST_VHE_GP_BASE 0x4>;
    mux-shift = <10>;  //2+REG_CKG_BIST_VHE_GP_OFFSET
    mux-width = <3>;
    gate-shift = <8>;  //0+REG_CKG_BIST_VHE_GP_OFFSET
    auto-enable = <1>;
};

CLK_vhe: CLK_vhe {
    #clock-cells = <0>;
    compatible = "sstar,composite-clock";
    clocks = <&CLK_venpll_clk>,<&CLK_mpll_576m>,<&CLK_miupll_clk>,<&CLK_upll_480m>,<&CLK_mpll_432m>,<&CLK_upll_384m>,<&CLK_upll_320m>,<&CLK_upll_480m_div2>;
    reg = <REG_CKG_VHE_BASE 0x4>;
    mux-shift = <2>;  //2+REG_CKG_VHE_OFFSET
    mux-width = <3>;
    gate-shift = <7>;  //0+REG_CKG_VHE_OFFSET
    auto-enable = <1>;
};

CLK_mfe: CLK_mfe {
    #clock-cells = <0>;
    compatible = "sstar,composite-clock";
    clocks = <&CLK_riscvpll_clk>,<&CLK_mpll_576m>,<&CLK_miupll_clk>,<&CLK_upll_480m>,<&CLK_mpll_432m>,<&CLK_upll_384m>,<&CLK_upll_320m>,<&CLK_upll_480m_div2>;
    reg = <REG_CKG_MFE_BASE 0x4>;
    mux-shift = <2>;  //2+REG_CKG_MFE_OFFSET
    mux-width = <3>;
    gate-shift = <0>;  //0+REG_CKG_MFE_OFFSET
    auto-enable = <1>;
};

CLK_ven_axi: CLK_ven_axi {
    #clock-cells = <0>;
    compatible = "sstar,composite-clock";
    clocks = <&CLK_venpll_clk>,<&CLK_mpll_576m>,<&CLK_miupll_clk>,<&CLK_upll_480m>,<&CLK_mpll_432m>,<&CLK_upll_384m>,<&CLK_upll_320m>,<&CLK_upll_480m_div2>;
    reg = <REG_CKG_VEN_AXI_BASE 0x4>;
    mux-shift = <10>;  //2+REG_CKG_VEN_AXI_OFFSET
    mux-width = <3>;
    gate-shift = <8>;  //0+REG_CKG_VEN_AXI_OFFSET
    auto-enable = <1>;
};

CLK_ven_scdn: CLK_ven_scdn {
    #clock-cells = <0>;
    compatible = "sstar,composite-clock";
    clocks = <&CLK_venpll_clk>,<&CLK_mpll_576m>,<&CLK_miupll_clk>,<&CLK_upll_480m>,<&CLK_mpll_432m>,<&CLK_upll_384m>,<&CLK_upll_320m>,<&CLK_upll_480m_div2>;
    reg = <REG_CKG_VEN_SCDN_BASE 0x4>;
    mux-shift = <10>;  //2+REG_CKG_VEN_SCDN_OFFSET
    mux-width = <3>;
    gate-shift = <8>;  //0+REG_CKG_VEN_SCDN_OFFSET
    auto-enable = <1>;
};

CLK_ven_sc_if: CLK_ven_sc_if {
    #clock-cells = <0>;
    compatible = "sstar,composite-clock";
    clocks = <&CLK_mpll_216m>,<&CLK_mpll_172m>,<&CLK_mpll_288m_div4>,<&CLK_xtali_12m>;
    reg = <REG_CKG_VEN_SC_IF_BASE 0x4>;
    mux-shift = <14>;  //2+REG_CKG_VEN_SC_IF_OFFSET
    mux-width = <2>;
    gate-shift = <12>;  //0+REG_CKG_VEN_SC_IF_OFFSET
    auto-enable = <1>;
};

CLK_bist_misc_gp: CLK_bist_misc_gp {
    #clock-cells = <0>;
    compatible = "sstar,composite-clock";
    clocks = <&CLK_upll_320m>,<&CLK_mpll_288m>,<&CLK_upll_480m_div2>,<&CLK_mpll_216m>,<&CLK_mpll_172m>,<&CLK_mpll_288m_div2>,<&CLK_mpll_432m_div8>,<&CLK_xtali_12m>;
    reg = <REG_CKG_BIST_MISC_GP_BASE 0x4>;
    mux-shift = <10>;  //2+REG_CKG_BIST_MISC_GP_OFFSET
    mux-width = <3>;
    gate-shift = <8>;  //0+REG_CKG_BIST_MISC_GP_OFFSET
    auto-enable = <1>;
};

/* CLK_bist_sc_gp: CLK_bist_sc_gp {
    #clock-cells = <0>;
    compatible = "sstar,composite-clock";
    clocks = <&CLK_upll_320m>,<&CLK_mpll_288m>,<&CLK_upll_480m_div2>,<&CLK_mpll_216m>,<&CLK_mpll_172m>,<&CLK_mpll_288m_div2>,<&CLK_mpll_432m_div8>,<&CLK_xtali_12m>;
    reg = <REG_CKG_BIST_SC_GP_BASE 0x4>;
    mux-shift = <2>;  //2+REG_CKG_BIST_SC_GP_OFFSET
    mux-width = <3>;
    gate-shift = <0>;  //0+REG_CKG_BIST_SC_GP_OFFSET
    auto-enable = <1>;
}; */

CLK_jpe: CLK_jpe {
    #clock-cells = <0>;
    compatible = "sstar,composite-clock";
    clocks = <&CLK_upll_480m>,<&CLK_mpll_576m>,<&CLK_upll_320m>,<&CLK_upll_384m>,<&CLK_upll_480m_div2>,<&CLK_mpll_288m_div8>,<&CLK_mpll_172m>,<&CLK_mpll_288m_div4>;
    reg = <REG_CKG_JPE_BASE 0x4>;
    mux-shift = <2>;  //2+REG_CKG_JPE_OFFSET
    mux-width = <3>;
    gate-shift = <0>;  //0+REG_CKG_JPE_OFFSET
    auto-enable = <1>;
};

CLK_aesdma: CLK_aesdma {
    #clock-cells = <0>;
    compatible = "sstar,composite-clock";
    clocks = <&CLK_miupll_clk>,<&CLK_mpll_288m>,<&CLK_mpll_172m>,<&CLK_otp_p>;
    reg = <REG_CKG_AESDMA_BASE 0x4>;
    mux-shift = <2>;  //2+REG_CKG_AESDMA_OFFSET
    mux-width = <2>;
    gate-shift = <0>;  //0+REG_CKG_AESDMA_OFFSET
    glitch-shift = <4>;  //4+REG_CKG_AESDMA_OFFSET
    auto-enable = <1>;
};

CLK_sdio: CLK_sdio {
    #clock-cells = <0>;
    compatible = "sstar,composite-clock";
    clocks = <&CLK_upll_384m_div8>,<&CLK_mpll_86m_div2>,<&CLK_upll_320m_div8>,<&CLK_mpll_288m_div8>,<&CLK_upll_320m_div10>,<&CLK_upll_320m_div16>,<&CLK_xtali_12m>,<&CLK_xtali_12m_div40>,<&CLK_spi_synth_pll>,<&CLK_mpll_432m>,<&CLK_upll_384m>,<&CLK_upll_320m>,<&CLK_mpll_288m>,<&CLK_mpll_216m>,<&CLK_mpll_432m_div4>,<&CLK_mpll_86m>;
    reg = <REG_CKG_SDIO_BASE 0x4>;
    mux-shift = <2>;  //2+REG_CKG_SDIO_OFFSET
    mux-width = <4>;
    gate-shift = <0>;  //0+REG_CKG_SDIO_OFFSET
    auto-enable = <1>;
};

CLK_sd: CLK_sd {
    #clock-cells = <0>;
    compatible = "sstar,composite-clock";
    clocks = <&CLK_upll_384m_div8>,<&CLK_mpll_86m_div2>,<&CLK_upll_320m_div8>,<&CLK_mpll_288m_div8>,<&CLK_upll_320m_div10>,<&CLK_upll_320m_div16>,<&CLK_xtali_12m>,<&CLK_xtali_12m_div40>,<&CLK_spi_synth_pll>,<&CLK_mpll_432m>,<&CLK_upll_384m>,<&CLK_upll_320m>,<&CLK_mpll_288m>,<&CLK_mpll_216m>,<&CLK_sd_1x_p>,<&CLK_sd_2x_p>;
    reg = <REG_CKG_SD_BASE 0x4>;
    mux-shift = <2>;  //2+REG_CKG_SD_OFFSET
    mux-width = <4>;
    gate-shift = <0>;  //0+REG_CKG_SD_OFFSET
    auto-enable = <1>;
};

CLK_fcie: CLK_fcie {
    #clock-cells = <0>;
    compatible = "sstar,composite-clock";
    clocks = <&CLK_upll_384m_div8>,<&CLK_mpll_86m_div2>,<&CLK_upll_320m_div8>,<&CLK_mpll_288m_div8>,<&CLK_upll_320m_div10>,<&CLK_upll_320m_div16>,<&CLK_xtali_12m>,<&CLK_xtali_12m_div40>,<&CLK_spi_synth_pll>,<&CLK_mpll_432m>,<&CLK_upll_384m>,<&CLK_upll_320m>,<&CLK_mpll_288m>,<&CLK_mpll_216m>,<&CLK_fcie_1x_p>,<&CLK_fcie_2x_p>;
    reg = <REG_CKG_FCIE_BASE 0x4>;
    mux-shift = <2>;  //2+REG_CKG_FCIE_OFFSET
    mux-width = <4>;
    gate-shift = <0>;  //0+REG_CKG_FCIE_OFFSET
    auto-enable = <1>;
};

/* CLK_ecc: CLK_ecc {
    #clock-cells = <0>;
    compatible = "sstar,composite-clock";
    clocks = <&CLK_upll_320m_div2>,<&CLK_mpll_432m_div4>,<&CLK_mpll_432m_div8>,<&CLK_xtali_12m>;
    reg = <REG_CKG_ECC_BASE 0x4>;
    mux-shift = <2>;  //2+REG_CKG_ECC_OFFSET
    mux-width = <2>;
    gate-shift = <0>;  //0+REG_CKG_ECC_OFFSET
    auto-enable = <1>;
}; */

CLK_sd_syn: CLK_sd_syn {
    #clock-cells = <0>;
    compatible = "sstar,composite-clock";
    clocks = <&CLK_mpll_216m>,<&CLK_mpll_432m>,<&CLK_xtali_12m>,<&CLK_VOID>;
    reg = <REG_CKG_SD_SYN_BASE 0x4>;
    mux-shift = <10>;  //2+REG_CKG_SD_SYN_OFFSET
    mux-width = <2>;
    gate-shift = <8>;  //0+REG_CKG_SD_SYN_OFFSET
    glitch-shift = <12>;  //4+REG_CKG_SD_SYN_OFFSET
    auto-enable = <1>;
};

CLK_fcie_syn: CLK_fcie_syn {
    #clock-cells = <0>;
    compatible = "sstar,composite-clock";
    clocks = <&CLK_mpll_216m>,<&CLK_mpll_432m>,<&CLK_xtali_12m>,<&CLK_VOID>;
    reg = <REG_CKG_FCIE_SYN_BASE 0x4>;
    mux-shift = <2>;  //2+REG_CKG_FCIE_SYN_OFFSET
    mux-width = <2>;
    gate-shift = <0>;  //0+REG_CKG_FCIE_SYN_OFFSET
    glitch-shift = <4>;  //4+REG_CKG_FCIE_SYN_OFFSET
    auto-enable = <1>;
};

/* CLK_bist_isp_gp: CLK_bist_isp_gp {
    #clock-cells = <0>;
    compatible = "sstar,composite-clock";
    clocks = <&CLK_upll_320m>,<&CLK_mpll_288m>,<&CLK_upll_480m_div2>,<&CLK_mpll_216m>,<&CLK_mpll_172m>,<&CLK_mpll_288m_div2>,<&CLK_mpll_432m_div8>,<&CLK_xtali_12m>;
    reg = <REG_CKG_BIST_ISP_GP_BASE 0x4>;
    mux-shift = <7>;  //2+REG_CKG_BIST_ISP_GP_OFFSET
    mux-width = <3>;
    gate-shift = <5>;  //0+REG_CKG_BIST_ISP_GP_OFFSET
    auto-enable = <1>;
}; */

CLK_isp: CLK_isp {
    #clock-cells = <0>;
    compatible = "sstar,composite-clock";
    clocks = <&CLK_isppll_clk>,<&CLK_mpll_288m>,<&CLK_upll_480m>,<&CLK_mpll_216m>,<&CLK_mpll_432m>,<&CLK_mpll_123m>,<&CLK_mpll_576m>,<&CLK_upll_320m>;
    reg = <REG_CKG_ISP_BASE 0x4>;
    mux-shift = <10>;  //2+REG_CKG_ISP_OFFSET
    mux-width = <3>;
    gate-shift = <8>;  //0+REG_CKG_ISP_OFFSET
    auto-enable = <1>;
};

CLK_dsc_enc1: CLK_dsc_enc1 {
    #clock-cells = <0>;
    compatible = "sstar,composite-clock";
    clocks = <&CLK_mpll_432m>,<&CLK_upll_384m>,<&CLK_mpll_288m>,<&CLK_mpll_216m>,<&CLK_mpll_345m>,<&CLK_VOID>,<&CLK_VOID>,<&CLK_VOID>;
    reg = <REG_CKG_DSC_ENC1_BASE 0x4>;
    mux-shift = <10>;  //2+REG_CKG_DSC_ENC1_OFFSET
    mux-width = <3>;
    gate-shift = <8>;  //0+REG_CKG_DSC_ENC1_OFFSET
    auto-enable = <1>;
};

CLK_dsc_dec1: CLK_dsc_dec1 {
    #clock-cells = <0>;
    compatible = "sstar,composite-clock";
    clocks = <&CLK_mpll_432m>,<&CLK_upll_384m>,<&CLK_mpll_288m>,<&CLK_mpll_216m>,<&CLK_mpll_345m>,<&CLK_VOID>,<&CLK_VOID>,<&CLK_VOID>;
    reg = <REG_CKG_DSC_DEC1_BASE 0x4>;
    mux-shift = <10>;  //2+REG_CKG_DSC_DEC1_OFFSET
    mux-width = <3>;
    gate-shift = <8>;  //0+REG_CKG_DSC_DEC1_OFFSET
    auto-enable = <1>;
};

CLK_fclk1: CLK_fclk1 {
    #clock-cells = <0>;
    compatible = "sstar,composite-clock";
    clocks = <&CLK_isppll_clk>,<&CLK_mpll_288m>,<&CLK_mpll_576m>,<&CLK_mpll_216m>,<&CLK_mpll_432m>,<&CLK_mpll_123m>,<&CLK_mpll_86m>,<&CLK_upll_320m>;
    reg = <REG_CKG_FCLK1_BASE 0x4>;
    mux-shift = <2>;  //2+REG_CKG_FCLK1_OFFSET
    mux-width = <3>;
    gate-shift = <0>;  //0+REG_CKG_FCLK1_OFFSET
    auto-enable = <1>;
};

CLK_sc_disp_216: CLK_sc_disp_216 {
    #clock-cells = <0>;
    compatible = "sstar,composite-clock";
    clocks = <&CLK_mpll_216m>,<&CLK_VOID>,<&CLK_VOID>,<&CLK_VOID>;
    reg = <REG_CKG_SC_DISP_216_BASE 0x4>;
    mux-shift = <2>;  //2+REG_CKG_SC_DISP_216_OFFSET
    mux-width = <2>;
    gate-shift = <0>;  //0+REG_CKG_SC_DISP_216_OFFSET
    auto-enable = <1>;
};

CLK_disp_pixel_0: CLK_disp_pixel_0 {
    #clock-cells = <0>;
    compatible = "sstar,composite-clock";
    clocks = <&CLK_mpll_432m>,<&CLK_upll_384m>,<&CLK_upll_320m>,<&CLK_mpll_288m>,<&CLK_upll_480m_div2>,<&CLK_mpll_216m>,<&CLK_upll_384m_div2>,<&CLK_mpll_172m>,<&CLK_mpll_432m_div4>,<&CLK_disppll_clk>,<&CLK_disppll_clk_div2>,<&CLK_disppll_clk_div4>,<&CLK_VOID>,<&CLK_VOID>,<&CLK_VOID>,<&CLK_VOID>;
    reg = <REG_CKG_DISP_PIXEL_0_BASE 0x4>;
    mux-shift = <2>;  //2+REG_CKG_DISP_PIXEL_0_OFFSET
    mux-width = <4>;
    gate-shift = <0>;  //0+REG_CKG_DISP_PIXEL_0_OFFSET
    auto-enable = <1>;
};

CLK_jpd: CLK_jpd {
    #clock-cells = <0>;
    compatible = "sstar,composite-clock";
    clocks = <&CLK_upll_384m>,<&CLK_mpll_432m>,<&CLK_upll_320m>,<&CLK_mpll_288m>,<&CLK_upll_480m_div2>,<&CLK_mpll_216m>,<&CLK_mpll_172m>,<&CLK_upll_480m>;
    reg = <REG_CKG_JPD_BASE 0x4>;
    mux-shift = <2>;  //2+REG_CKG_JPD_OFFSET
    mux-width = <3>;
    gate-shift = <0>;  //0+REG_CKG_JPD_OFFSET
    auto-enable = <1>;
};

CLK_ive: CLK_ive {
    #clock-cells = <0>;
    compatible = "sstar,composite-clock";
    clocks = <&CLK_upll_480m>,<&CLK_mpll_172m>,<&CLK_mpll_432m>,<&CLK_mpll_123m>,<&CLK_mpll_576m>,<&CLK_upll_320m>,<&CLK_upll_384m>,<&CLK_upll_480m_div2>;
    reg = <REG_CKG_IVE_BASE 0x4>;
    mux-shift = <10>;  //2+REG_CKG_IVE_OFFSET
    mux-width = <3>;
    gate-shift = <8>;  //0+REG_CKG_IVE_OFFSET
    auto-enable = <1>;
};

CLK_ldcfeye: CLK_ldcfeye {
    #clock-cells = <0>;
    compatible = "sstar,composite-clock";
    clocks = <&CLK_isppll_clk>,<&CLK_upll_480m>,<&CLK_mpll_432m>,<&CLK_upll_384m>,<&CLK_upll_320m>,<&CLK_mpll_288m>,<&CLK_mpll_216m>,<&CLK_mpll_576m>;
    reg = <REG_CKG_LDCFEYE_BASE 0x4>;
    mux-shift = <2>;  //2+REG_CKG_LDCFEYE_OFFSET
    mux-width = <3>;
    gate-shift = <0>;  //0+REG_CKG_LDCFEYE_OFFSET
    auto-enable = <1>;
};

CLK_cvs: CLK_cvs {
    #clock-cells = <0>;
    compatible = "sstar,composite-clock";
    clocks = <&CLK_upll_480m>,<&CLK_mpll_576m>,<&CLK_mpll_432m>,<&CLK_upll_384m>,<&CLK_upll_320m>,<&CLK_mpll_288m>,<&CLK_mpll_216m>,<&CLK_mpll_172m>;
    reg = <REG_CKG_CVS_BASE 0x4>;
    mux-shift = <10>;  //2+REG_CKG_CVS_OFFSET
    mux-width = <3>;
    gate-shift = <8>;  //0+REG_CKG_CVS_OFFSET
    auto-enable = <1>;
};

CLK_emac_ahb: CLK_emac_ahb {
    #clock-cells = <0>;
    compatible = "sstar,composite-clock";
    clocks = <&CLK_mpll_288m_div2>,<&CLK_mpll_123m>,<&CLK_mpll_86m>,<&CLK_emac_testrx125_in_lan>;
    reg = <REG_CKG_EMAC_AHB_BASE 0x4>;
    mux-shift = <2>;  //2+REG_CKG_EMAC_AHB_OFFSET
    mux-width = <2>;
    gate-shift = <0>;  //0+REG_CKG_EMAC_AHB_OFFSET
    auto-enable = <1>;
};

CLK_gmac0_gmii: CLK_gmac0_gmii {
    #clock-cells = <0>;
    compatible = "sstar,composite-clock";
    clocks = <&CLK_gmacpll_250_div2>,<&CLK_gmacpll_25a>,<&CLK_gmacpll_250_div100>,<&CLK_gmac0_external_ref_buf>;
    reg = <REG_CKG_GMAC0_GMII_BASE 0x4>;
    mux-shift = <2>;  //2+REG_CKG_GMAC0_GMII_OFFSET
    mux-width = <2>;
    gate-shift = <0>;  //0+REG_CKG_GMAC0_GMII_OFFSET
    auto-enable = <1>;
};

CLK_gmac1_gmii: CLK_gmac1_gmii {
    #clock-cells = <0>;
    compatible = "sstar,composite-clock";
    clocks = <&CLK_gmacpll_250_div2>,<&CLK_gmacpll_25b>,<&CLK_gmacpll_250_div100>,<&CLK_gmac1_external_ref_buf>;
    reg = <REG_CKG_GMAC1_GMII_BASE 0x4>;
    mux-shift = <2>;  //2+REG_CKG_GMAC1_GMII_OFFSET
    mux-width = <2>;
    gate-shift = <0>;  //0+REG_CKG_GMAC1_GMII_OFFSET
    auto-enable = <1>;
};

CLK_gphy0_ref: CLK_gphy0_ref {
    #clock-cells = <0>;
    compatible = "sstar,composite-clock";
    clocks = <&CLK_gmacpll_25a>,<&CLK_gmacpll_250_div5>,<&CLK_VOID>,<&CLK_VOID>;
    reg = <REG_CKG_GPHY0_REF_BASE 0x4>;
    mux-shift = <2>;  //2+REG_CKG_GPHY0_REF_OFFSET
    mux-width = <2>;
    gate-shift = <0>;  //0+REG_CKG_GPHY0_REF_OFFSET
    auto-enable = <1>;
};

CLK_gphy1_ref: CLK_gphy1_ref {
    #clock-cells = <0>;
    compatible = "sstar,composite-clock";
    clocks = <&CLK_gmacpll_25b>,<&CLK_gmacpll_250_div5>,<&CLK_VOID>,<&CLK_VOID>;
    reg = <REG_CKG_GPHY1_REF_BASE 0x4>;
    mux-shift = <2>;  //2+REG_CKG_GPHY1_REF_OFFSET
    mux-width = <2>;
    gate-shift = <0>;  //0+REG_CKG_GPHY1_REF_OFFSET
    auto-enable = <1>;
};

CLK_au_sys_384: CLK_au_sys_384 {
    #clock-cells = <0>;
    compatible = "sstar,composite-clock";
    clocks = <&CLK_VOID>,<&CLK_upll_480m>,<&CLK_mpll_432m>,<&CLK_bachpll_384m>;
    reg = <REG_CKG_AU_SYS_384_BASE 0x4>;
    mux-shift = <2>;  //2+REG_CKG_AU_SYS_384_OFFSET
    mux-width = <2>;
    gate-shift = <0>;  //0+REG_CKG_AU_SYS_384_OFFSET
    auto-enable = <1>;
    propagate = <1>;
};

CLK_au_sys_432: CLK_au_sys_432 {
    #clock-cells = <0>;
    compatible = "sstar,composite-clock";
    clocks = <&CLK_mpll_432m>,<&CLK_upll_480m>,<&CLK_upll_384m>,<&CLK_bachpll_384m>;
    reg = <REG_CKG_AU_SYS_432_BASE 0x4>;
    mux-shift = <2>;  //2+REG_CKG_AU_SYS_432_OFFSET
    mux-width = <2>;
    gate-shift = <0>;  //0+REG_CKG_AU_SYS_432_OFFSET
    auto-enable = <1>;
};

/* CLK_bist_miu0: CLK_bist_miu0 {
    #clock-cells = <0>;
    compatible = "sstar,composite-clock";
    clocks = <&CLK_upll_320m>,<&CLK_mpll_288m>,<&CLK_upll_480m_div2>,<&CLK_mpll_216m>,<&CLK_mpll_172m>,<&CLK_mpll_288m_div2>,<&CLK_mpll_432m_div8>,<&CLK_xtali_12m>;
    reg = <REG_CKG_BIST_MIU0_BASE 0x4>;
    mux-shift = <2>;  //2+REG_CKG_BIST_MIU0_OFFSET
    mux-width = <3>;
    gate-shift = <0>;  //0+REG_CKG_BIST_MIU0_OFFSET
    auto-enable = <1>;
}; */

/* CLK_pad_test: CLK_pad_test {
    #clock-cells = <0>;
    compatible = "sstar,composite-clock";
    clocks = <&CLK_mpll_288m_div2>,<&CLK_mpll_123m>,<&CLK_mpll_288m_div4>,<&CLK_VOID>;
    reg = <REG_CKG_PAD_TEST_BASE 0x4>;
    mux-shift = <2>;  //2+REG_CKG_PAD_TEST_OFFSET
    mux-width = <2>;
    gate-shift = <0>;  //0+REG_CKG_PAD_TEST_OFFSET
    auto-enable = <1>;
}; */

/* CLK_otp: CLK_otp {
    #clock-cells = <0>;
    compatible = "sstar,composite-clock";
    clocks = <&CLK_xtali_12m>,<&CLK_VOID>,<&CLK_VOID>,<&CLK_VOID>;
    reg = <REG_CKG_OTP_BASE 0x4>;
    mux-shift = <2>;  //2+REG_CKG_OTP_OFFSET
    mux-width = <2>;
    gate-shift = <0>;  //0+REG_CKG_OTP_OFFSET
    auto-enable = <1>;
}; */

CLK_pm_pwm: CLK_pm_pwm {
    #clock-cells = <0>;
    compatible = "sstar,composite-clock";
    clocks = <&CLK_12m_mux>,<&CLK_24m_mux>,<&CLK_12m_mux_div2>,<&CLK_12m_mux_div4>,<&CLK_12m_mux_div8>,<&CLK_rtcpll_clk_div16>,<&CLK_rtcpll_clk_div96>,<&CLK_VOID>;
    reg = <REG_CKG_PM_PWM_BASE 0x4>;
    mux-shift = <12>;  //2+REG_CKG_PM_PWM_OFFSET
    mux-width = <3>;
    gate-shift = <10>;  //0+REG_CKG_PM_PWM_OFFSET
    auto-enable = <1>;
};

CLK_radar_adc: CLK_radar_adc {
    #clock-cells = <0>;
    compatible = "sstar,composite-clock";
    clocks = <&CLK_24m_mux>,<&CLK_12m_mux>,<&CLK_upll_radar_20m>,<&CLK_rtcpll_clk_div8>;
    reg = <REG_CKG_RADAR_ADC_BASE 0x4>;
    mux-shift = <2>;  //2+REG_CKG_RADAR_ADC_OFFSET
    mux-width = <2>;
    gate-shift = <0>;  //0+REG_CKG_RADAR_ADC_OFFSET
    auto-enable = <1>;
};

CLK_pm_uart0: CLK_pm_uart0 {
    #clock-cells = <0>;
    compatible = "sstar,composite-clock";
    clocks = <&CLK_12m_mux>,<&CLK_24m_mux>,<&CLK_rtcpll_clk_div16>,<&CLK_12m_mux_div2>;
    reg = <REG_CKG_PM_UART_BASE 0x4>;
    mux-shift = <2>;  //2+REG_CKG_PM_UART_OFFSET
    mux-width = <2>;
    gate-shift = <0>;  //0+REG_CKG_PM_UART_OFFSET
    auto-enable = <1>;
};

CLK_pm_fuart0: CLK_pm_fuart0 {
    #clock-cells = <0>;
    compatible = "sstar,composite-clock";
    clocks = <&CLK_12m_mux>,<&CLK_24m_mux>,<&CLK_rtcpll_clk_div16>,<&CLK_12m_mux_div2>;
    reg = <REG_CKG_PM_FUART0_BASE 0x4>;
    mux-shift = <10>;  //2+REG_CKG_PM_FUART0_OFFSET
    mux-width = <2>;
    gate-shift = <8>;  //0+REG_CKG_PM_FUART0_OFFSET
    auto-enable = <1>;
};

CLK_pm_pspi0: CLK_pm_pspi0 {
    #clock-cells = <0>;
    compatible = "sstar,composite-clock";
    clocks = <&CLK_48m_mux>,<&CLK_rtcpll_clk_div2>,<&CLK_rtcpll_clk_div4>,<&CLK_rtcpll_clk_div8>,<&CLK_upll_384m_div4>,<&CLK_upll_384m_div8>,<&CLK_VOID>,<&CLK_VOID>;
    reg = <REG_CKG_PSPI0_BASE 0x4>;
    mux-shift = <12>;  //2+REG_CKG_PSPI0_OFFSET
    mux-width = <3>;
    gate-shift = <10>;  //0+REG_CKG_PSPI0_OFFSET
    auto-enable = <1>;
};

CLK_pm_mspi0: CLK_pm_mspi0 {
    #clock-cells = <0>;
    compatible = "sstar,composite-clock";
    clocks = <&CLK_48m_mux>,<&CLK_rtcpll_clk_div2>,<&CLK_rtcpll_clk_div4>,<&CLK_rtcpll_clk_div8>,<&CLK_upll_384m_div4>,<&CLK_upll_384m_div8>,<&CLK_VOID>,<&CLK_VOID>;
    reg = <REG_CKG_PM_MSPI0_BASE 0x4>;
    mux-shift = <2>;  //2+REG_CKG_PM_MSPI0_OFFSET
    mux-width = <3>;
    gate-shift = <0>;  //0+REG_CKG_PM_MSPI0_OFFSET
    auto-enable = <1>;
};

CLK_pm_mspi1: CLK_pm_mspi1 {
    #clock-cells = <0>;
    compatible = "sstar,composite-clock";
    clocks = <&CLK_48m_mux>,<&CLK_rtcpll_clk_div2>,<&CLK_rtcpll_clk_div4>,<&CLK_rtcpll_clk_div8>,<&CLK_upll_384m_div4>,<&CLK_upll_384m_div8>,<&CLK_VOID>,<&CLK_VOID>;
    reg = <REG_CKG_PM_MSPI1_BASE 0x4>;
    mux-shift = <10>;  //2+REG_CKG_PM_MSPI1_OFFSET
    mux-width = <3>;
    gate-shift = <8>;  //0+REG_CKG_PM_MSPI1_OFFSET
    auto-enable = <1>;
};

CLK_pm_miic0: CLK_pm_miic0 {
    #clock-cells = <0>;
    compatible = "sstar,composite-clock";
    clocks = <&CLK_12m_mux>,<&CLK_24m_mux>,<&CLK_rtcpll_clk_div8>,<&CLK_rtcpll_clk_div16>;
    reg = <REG_CKG_PM_MIIC0_BASE 0x4>;
    mux-shift = <2>;  //2+REG_CKG_PM_MIIC0_OFFSET
    mux-width = <2>;
    gate-shift = <0>;  //0+REG_CKG_PM_MIIC0_OFFSET
    auto-enable = <1>;
};

CLK_pm_miic1: CLK_pm_miic1 {
    #clock-cells = <0>;
    compatible = "sstar,composite-clock";
    clocks = <&CLK_12m_mux>,<&CLK_24m_mux>,<&CLK_rtcpll_clk_div8>,<&CLK_rtcpll_clk_div16>;
    reg = <REG_CKG_PM_MIIC1_BASE 0x4>;
    mux-shift = <14>;  //2+REG_CKG_PM_MIIC1_OFFSET
    mux-width = <2>;
    gate-shift = <12>;  //0+REG_CKG_PM_MIIC1_OFFSET
    auto-enable = <1>;
};

CLK_pm_pwr_ctl: CLK_pm_pwr_ctl {
    #clock-cells = <0>;
    compatible = "sstar,composite-clock";
    clocks = <&CLK_24m_mux>,<&CLK_12m_mux_div8>,<&CLK_12m_mux>,<&CLK_VOID>;
    reg = <REG_CKG_PM_PWR_CTL_BASE 0x4>;
    mux-shift = <2>;  //2+REG_CKG_PM_PWR_CTL_OFFSET
    mux-width = <2>;
    gate-shift = <0>;  //0+REG_CKG_PM_PWR_CTL_OFFSET
    ignore = <1>;
};

CLK_mcu_pm: CLK_mcu_pm {
    #clock-cells = <0>;
    compatible = "sstar,composite-clock";
    clocks = <&CLK_48m_mux>,<&CLK_mpll_86m>,<&CLK_mpll_216m>,<&CLK_mpll_432m_div4>,<&CLK_rtcpll_clk>,<&CLK_12m_mux>,<&CLK_rtcpll_clk_div2>,<&CLK_RTC_CLK_32K>,<&CLK_24m_mux>,<&CLK_mpll_288m>,<&CLK_mpll_345m>,<&CLK_upll_320m>,<&CLK_VOID>,<&CLK_VOID>,<&CLK_VOID>,<&CLK_VOID>;
    reg = <REG_CKG_PM_MCU_BASE 0x4>;
    mux-shift = <2>;  //2+REG_CKG_PM_MCU_OFFSET
    mux-width = <4>;
    gate-shift = <0>;  //0+REG_CKG_PM_MCU_OFFSET
    glitch-shift = <7>;  //7+REG_CKG_PM_MCU_OFFSET
    auto-enable = <1>;
};

/* CLK_spi_pm: CLK_spi_pm {
    #clock-cells = <0>;
    compatible = "sstar,composite-clock";
    clocks = <&CLK_24m_mux>,<&CLK_upll_384m_div4>,<&CLK_upll_384m_div8>,<&CLK_rtcpll_clk>,<&CLK_mpll_432m_div8>,<&CLK_rtcpll_clk_div2>,<&CLK_upll_320m_div2>,<&CLK_48m_mux>;
    reg = <REG_CKG_PM_SPI_BASE 0x4>;
    mux-shift = <10>;  //2+REG_CKG_PM_SPI_OFFSET
    mux-width = <3>;
    gate-shift = <8>;  //0+REG_CKG_PM_SPI_OFFSET
    glitch-shift = <13>;  //5+REG_CKG_PM_SPI_OFFSET
    auto-enable = <1>;
}; */

/* CLK_pm_sleep: CLK_pm_sleep {
    #clock-cells = <0>;
    compatible = "sstar,composite-clock";
    clocks = <&CLK_12m_mux>,<&CLK_24m_mux>,<&CLK_VOID>,<&CLK_VOID>;
    reg = <REG_CKG_PM_SLEEP_BASE 0x4>;
    mux-shift = <12>;  //2+REG_CKG_PM_SLEEP_OFFSET
    mux-width = <2>;
    auto-enable = <1>;
}; */

CLK_sar: CLK_sar {
    #clock-cells = <0>;
    compatible = "sstar,composite-clock";
    clocks = <&CLK_12m_mux>,<&CLK_24m_mux>,<&CLK_VOID>,<&CLK_VOID>;
    reg = <REG_CKG_SAR_BASE 0x4>;
    mux-shift = <7>;  //2+REG_CKG_SAR_OFFSET
    mux-width = <2>;
    gate-shift = <5>;  //0+REG_CKG_SAR_OFFSET
    auto-enable = <1>;
};

/* CLK_rtc: CLK_rtc {
    #clock-cells = <0>;
    compatible = "sstar,composite-clock";
    clocks = <&CLK_12m_mux>,<&CLK_24m_mux>,<&CLK_RTC_CLK_32K>,<&CLK_VOID>;
    reg = <REG_CKG_RTC_BASE 0x4>;
    mux-shift = <2>;  //2+REG_CKG_RTC_OFFSET
    mux-width = <2>;
    gate-shift = <0>;  //0+REG_CKG_RTC_OFFSET
    auto-enable = <1>;
}; */

CLK_ir: CLK_ir {
    #clock-cells = <0>;
    compatible = "sstar,composite-clock";
    clocks = <&CLK_24m_mux>,<&CLK_12m_mux>,<&CLK_12m_mux_div2>,<&CLK_RTC_CLK_32K>;
    reg = <REG_CKG_IR_BASE 0x4>;
    mux-shift = <7>;  //2+REG_CKG_IR_OFFSET
    mux-width = <2>;
    gate-shift = <5>;  //0+REG_CKG_IR_OFFSET
    auto-enable = <1>;
};

CLK_wdt: CLK_wdt {
    #clock-cells = <0>;
    compatible = "sstar,composite-clock";
    clocks = <&CLK_12m_mux>,<&CLK_12m_mux_div2>,<&CLK_12m_mux_div4>,<&CLK_24m_mux>;
    reg = <REG_CKG_WDT_BASE 0x4>;
    mux-shift = <6>;  //2+REG_CKG_WDT_OFFSET
    mux-width = <2>;
    gate-shift = <4>;  //0+REG_CKG_WDT_OFFSET
    auto-enable = <1>;
};

CLK_imi_pm: CLK_imi_pm {
    #clock-cells = <0>;
    compatible = "sstar,composite-clock";
    clocks = <&CLK_24m_mux>,<&CLK_rtcpll_clk_div2>,<&CLK_upll_384m_div4>,<&CLK_rtcpll_clk_div4>,<&CLK_mpll_123m>,<&CLK_VOID>,<&CLK_VOID>,<&CLK_VOID>;
    reg = <REG_CKG_IMI_PM_BASE 0x4>;
    mux-shift = <2>;  //2+REG_CKG_IMI_PM_OFFSET
    mux-width = <3>;
    gate-shift = <0>;  //0+REG_CKG_IMI_PM_OFFSET
    auto-enable = <1>;
};

CLK_isp_pm: CLK_isp_pm {
    #clock-cells = <0>;
    compatible = "sstar,composite-clock";
    clocks = <&CLK_12m_mux>,<&CLK_24m_mux>,<&CLK_rtcpll_clk_div16>,<&CLK_upll_320m_div10>,<&CLK_rtcpll_clk_div6>,<&CLK_48m_mux>,<&CLK_rtcpll_clk_div48>,<&CLK_rtcpll_clk_div4>;
    reg = <REG_CKG_ISP_PM_BASE 0x4>;
    mux-shift = <2>;  //2+REG_CKG_ISP_PM_OFFSET
    mux-width = <3>;
    gate-shift = <0>;  //0+REG_CKG_ISP_PM_OFFSET
    auto-enable = <1>;
};

CLK_pir_pm: CLK_pir_pm {
    #clock-cells = <0>;
    compatible = "sstar,composite-clock";
    clocks = <&CLK_12m_mux>,<&CLK_rtcpll_clk_div6>,<&CLK_rtcpll_clk_div16>,<&CLK_24m_mux>,<&CLK_12m_mux_div2>,<&CLK_12m_mux_div4>,<&CLK_rtcpll_clk_div32>,<&CLK_rtcpll_clk_div64>;
    reg = <REG_CKG_PIR_BASE 0x4>;
    mux-shift = <7>;  //2+REG_CKG_PIR_OFFSET
    mux-width = <3>;
    gate-shift = <5>;  //0+REG_CKG_PIR_OFFSET
    auto-enable = <1>;
};

CLK_jpe_pm: CLK_jpe_pm {
    #clock-cells = <0>;
    compatible = "sstar,composite-clock";
    clocks = <&CLK_12m_mux>,<&CLK_rtcpll_clk_div6>,<&CLK_upll_320m_div10>,<&CLK_24m_mux>,<&CLK_rtcpll_clk_div8>,<&CLK_48m_mux>,<&CLK_rtcpll_clk_div4>,<&CLK_rtcpll_clk_div2>;
    reg = <REG_CKG_JPE_PM_BASE 0x4>;
    mux-shift = <12>;  //2+REG_CKG_JPE_PM_OFFSET
    mux-width = <3>;
    gate-shift = <10>;  //0+REG_CKG_JPE_PM_OFFSET
    auto-enable = <1>;
};

CLK_bist_pm: CLK_bist_pm {
    #clock-cells = <0>;
    compatible = "sstar,composite-clock";
    clocks = <&CLK_rtcpll_clk>,<&CLK_mpll_172m>,<&CLK_mpll_288m_div2>,<&CLK_mpll_432m_div8>,<&CLK_12m_mux>,<&CLK_24m_mux>,<&CLK_VOID>,<&CLK_VOID>;
    reg = <REG_CKG_BIST_PM_BASE 0x4>;
    mux-shift = <2>;  //2+REG_CKG_BIST_PM_OFFSET
    mux-width = <3>;
    gate-shift = <0>;  //0+REG_CKG_BIST_PM_OFFSET
    auto-enable = <1>;
};

CLK_dmic_pm: CLK_dmic_pm {
    #clock-cells = <0>;
    compatible = "sstar,composite-clock";
    clocks = <&CLK_rtcpll_clk_div8>,<&CLK_24m_mux>,<&CLK_rtcpll_clk_div16>,<&CLK_12m_mux>,<&CLK_rtcpll_clk_div96>,<&CLK_rtcpll_clk_div384>,<&CLK_VOID>,<&CLK_VOID>;
    reg = <REG_CKG_DMIC_PM_BASE 0x4>;
    mux-shift = <7>;  //2+REG_CKG_DMIC_PM_OFFSET
    mux-width = <3>;
    gate-shift = <5>;  //0+REG_CKG_DMIC_PM_OFFSET
    auto-enable = <1>;
};

CLK_xtal_usb30_drd: CLK_xtal_usb30_drd {
    #clock-cells = <0>;
    compatible = "sstar,composite-clock";
    clocks = <&CLK_12m_mux>,<&CLK_VOID>,<&CLK_VOID>,<&CLK_VOID>;
    reg = <REG_CKG_XTAL_USB30_DRD_BASE 0x4>;
    mux-shift = <2>;  //2+REG_CKG_XTAL_USB30_DRD_OFFSET
    mux-width = <2>;
    gate-shift = <0>;  //0+REG_CKG_XTAL_USB30_DRD_OFFSET
    auto-enable = <1>;
};

CLK_usb_32k: CLK_usb_32k {
    #clock-cells = <0>;
    compatible = "sstar,composite-clock";
    clocks = <&CLK_RTC_CLK_32K>,<&CLK_VOID>,<&CLK_VOID>,<&CLK_VOID>;
    reg = <REG_CKG_USB_32K_BASE 0x4>;
    mux-shift = <10>;  //2+REG_CKG_USB_32K_OFFSET
    mux-width = <2>;
    gate-shift = <8>;  //0+REG_CKG_USB_32K_OFFSET
    auto-enable = <1>;
};

/* CLK_sr_mclk_pm: CLK_sr_mclk_pm {
    #clock-cells = <0>;
    compatible = "sstar,composite-clock";
    clocks = <&CLK_mpll_432m_div16>,<&CLK_mpll_288m_div4>,<&CLK_mpll_123m_div2>,<&CLK_mpll_432m_div8>,<&CLK_upll_384m_div8>,<&CLK_mpll_86m_div2>,<&CLK_mpll_288m_div8>,<&CLK_24m_mux>,<&CLK_mpll_86m_div4>,<&CLK_12m_mux>,<&CLK_mpll_86m_div16>,<&CLK_rtcpll_clk_div8>,<&CLK_rtcpll_clk_div16>,<&CLK_VOID>,<&CLK_VOID>,<&CLK_VOID>;
    reg = <REG_CKG_SR_MCLK_BASE 0x4>;
    mux-shift = <10>;  //2+REG_CKG_SR_MCLK_OFFSET
    mux-width = <4>;
    gate-shift = <8>;  //0+REG_CKG_SR_MCLK_OFFSET
    auto-enable = <1>;
}; */

CLK_ssi_dphy: CLK_ssi_dphy {
    #clock-cells = <0>;
    compatible = "sstar,composite-clock";
    clocks = <&CLK_upll_384m_div2>,<&CLK_mpll_172m>,<&CLK_mpll_288m_div2>,<&CLK_mpll_123m>,<&CLK_mpll_86m>,<&CLK_upll_384m_div8>,<&CLK_48m_mux>,<&CLK_24m_mux>,<&CLK_12m_mux>,<&CLK_rtcpll_clk>,<&CLK_rtcpll_clk_div2>,<&CLK_rtcpll_clk_div4>,<&CLK_rtcpll_clk_div6>,<&CLK_rtcpll_clk_div8>,<&CLK_rtcpll_clk_div16>,<&CLK_VOID>;
    reg = <REG_CKG_SSI_DPHY_BASE 0x4>;
    mux-shift = <2>;  //2+REG_CKG_SSI_DPHY_OFFSET
    mux-width = <4>;
    gate-shift = <0>;  //0+REG_CKG_SSI_DPHY_OFFSET
    auto-enable = <1>;
};

CLK_wdma: CLK_wdma {
    #clock-cells = <0>;
    compatible = "sstar,composite-clock";
    clocks = <&CLK_miu>;
    reg = <REG_DBG_WDMA_CLK_MIU_CKG_BASE 0x4>;
    gate-shift = <0>;  //0+REG_DBG_WDMA_CLK_MIU_CKG_OFFSET
    gate-enable = <1>;
    auto-enable = <1>;
};

/* for clock must be added by hand start */

CLK_rng: CLK_rng {
    #clock-cells = <0>;
    compatible = "sstar,composite-clock";
    clocks = <&CLK_xtali_12m>,<&CLK_upll_480m>;
    reg = <REG_CKG_RNG_BASE 0x4>;
    mux-shift = <2>;  //2+REG_CKG_RNG_OFFSET
    mux-width = <1>;
    gate-shift = <0>;  //0+REG_CKG_RNG_OFFSET
    auto-enable = <0>;
};

CLK_boot_p: CLK_boot_p {
    #clock-cells = <0>;
    compatible = "sstar,composite-clock";
    clocks = <&CLK_xtali_12m>,<&CLK_VOID>,<&CLK_VOID>,<&CLK_VOID>;
    reg = <REG_CKG_BOOT_BASE 0x4>;
    mux-shift = <2>;  //2+REG_CKG_BOOT_OFFSET
    mux-width = <2>;
    gate-shift = <0>;  //0+REG_CKG_BOOT_OFFSET
    auto-enable = <0>;
};

/* for clock must be added by hand end */

#ifdef CONFIG_MS_USCLK
usclk: usclk {
    compatible = "usclk";
    clocks = <&CLK_12m_mux>,
             <&CLK_12m_mux_div16>,
             <&CLK_12m_mux_div2>,
             <&CLK_12m_mux_div4>,
             <&CLK_12m_mux_div8>,
             <&CLK_24m_mux>,
             <&CLK_48m_mux>,
             <&CLK_RTC_CLK_32K>,
             <&CLK_VOID>,
             <&CLK_aesdma>,
             <&CLK_au_sys_384>,
             <&CLK_au_sys_432>,
             <&CLK_aupll_384m>,
             <&CLK_bachpll_384m>,
             <&CLK_bist>,
             <&CLK_bist_ipu_gp>,
             <&CLK_bist_isp_gp>,
             <&CLK_bist_mcu>,
             <&CLK_bist_misc_gp>,
             <&CLK_bist_miu0>,
             <&CLK_bist_pm>,
             <&CLK_bist_sc_gp>,
             <&CLK_bist_usb30_drd_gp>,
             <&CLK_bist_vhe_gp>,
             <&CLK_cpu_pll>,
             <&CLK_csi_mac_lptx_top_i_0>,
             <&CLK_csi_mac_lptx_top_i_1>,
             <&CLK_csi_mac_lptx_top_i_2>,
             <&CLK_csi_mac_lptx_top_i_3>,
             <&CLK_csi_mac_top_i_0>,
             <&CLK_csi_mac_top_i_1>,
             <&CLK_csi_mac_top_i_2>,
             <&CLK_csi_mac_top_i_3>,
             <&CLK_cvs>,
             <&CLK_ddr_syn>,
             <&CLK_ddrpll_clk>,
             <&CLK_disp_pixel_0>,
             <&CLK_disppll_clk>,
             <&CLK_disppll_clk_div2>,
             <&CLK_disppll_clk_div4>,
             <&CLK_disppll_clk_div8>,
             <&CLK_dmic_pm>,
             <&CLK_dsc_dec1>,
             <&CLK_dsc_enc1>,
             <&CLK_ecc>,
             <&CLK_emac_ahb>,
             <&CLK_emac_testrx125_in_lan>,
             <&CLK_eth_buf>,
             <&CLK_fcie>,
             <&CLK_fcie_1x_p>,
             <&CLK_fcie_2x_p>,
             <&CLK_fcie_syn>,
             <&CLK_fclk1>,
             <&CLK_fclk1_p>,
             <&CLK_fclk2_p>,
             <&CLK_fuart>,
             <&CLK_fuart0>,
             <&CLK_fuart0_synth_in>,
             <&CLK_fuart0_synth_out>,
             <&CLK_fuart1>,
             <&CLK_fuart1_synth_in>,
             <&CLK_fuart1_synth_out>,
             <&CLK_fuart2>,
             <&CLK_fuart2_synth_in>,
             <&CLK_fuart2_synth_out>,
             <&CLK_fuart3>,
             <&CLK_fuart3_synth_in>,
             <&CLK_fuart3_synth_out>,
             <&CLK_fuart4>,
             <&CLK_fuart4_synth_in>,
             <&CLK_fuart4_synth_out>,
             <&CLK_fuart5>,
             <&CLK_fuart5_synth_in>,
             <&CLK_fuart5_synth_out>,
             <&CLK_fuart6>,
             <&CLK_fuart6_synth_in>,
             <&CLK_fuart6_synth_out>,
             <&CLK_fuart7>,
             <&CLK_fuart7_synth_in>,
             <&CLK_fuart7_synth_out>,
             <&CLK_fuart_synth_in>,
             <&CLK_fuart_synth_out>,
             <&CLK_gmac0_external_ref_buf>,
             <&CLK_gmac0_gmii>,
             <&CLK_gmac1_external_ref_buf>,
             <&CLK_gmac1_gmii>,
             <&CLK_gmacpll_250>,
             <&CLK_gmacpll_250_div100>,
             <&CLK_gmacpll_250_div2>,
             <&CLK_gmacpll_250_div5>,
             <&CLK_gmacpll_25a>,
             <&CLK_gmacpll_25b>,
             <&CLK_gphy0_ref>,
             <&CLK_gphy1_ref>,
             <&CLK_imi_pm>,
             <&CLK_ipu>,
             <&CLK_ipuff>,
             <&CLK_ipupll_clk>,
             <&CLK_ir>,
             <&CLK_isp>,
             <&CLK_isp_p>,
             <&CLK_isp_pm>,
             <&CLK_isppll_clk>,
             <&CLK_isppll_clk_div16>,
             <&CLK_isppll_clk_div2>,
             <&CLK_isppll_clk_div4>,
             <&CLK_isppll_clk_div8>,
             <&CLK_ive>,
             <&CLK_jpd>,
             <&CLK_jpe>,
             <&CLK_jpe_pm>,
             <&CLK_ldcfeye>,
             <&CLK_live>,
             <&CLK_live_c>,
             <&CLK_mcu>,
             <&CLK_mcu_p>,
             <&CLK_mcu_pm>,
             <&CLK_mcu_pm_p>,
             <&CLK_mfe>,
             <&CLK_miic0>,
             <&CLK_miic1>,
             <&CLK_miic2>,
             <&CLK_miic3>,
             <&CLK_miic4>,
             <&CLK_miic5>,
             <&CLK_mipi_tx_dsi0>,
             <&CLK_miu>,
             <&CLK_miu2x_p>,
             <&CLK_miu_isp_gp_p>,
             <&CLK_miu_p>,
             <&CLK_miu_rec>,
             <&CLK_miu_sc_gp_p>,
             <&CLK_miu_vhe_gp_p>,
             <&CLK_miupll_clk>,
             <&CLK_mpll_123m>,
             <&CLK_mpll_123m_div2>,
             <&CLK_mpll_172m>,
             <&CLK_mpll_216m>,
             <&CLK_mpll_288m>,
             <&CLK_mpll_288m_div2>,
             <&CLK_mpll_288m_div4>,
             <&CLK_mpll_288m_div8>,
             <&CLK_mpll_345m>,
             <&CLK_mpll_432m>,
             <&CLK_mpll_432m_div16>,
             <&CLK_mpll_432m_div4>,
             <&CLK_mpll_432m_div8>,
             <&CLK_mpll_576m>,
             <&CLK_mpll_86m>,
             <&CLK_mpll_86m_div16>,
             <&CLK_mpll_86m_div2>,
             <&CLK_mpll_86m_div4>,
             <&CLK_mspi0>,
             <&CLK_mspi0_p>,
             <&CLK_mspi1>,
             <&CLK_mspi2>,
             <&CLK_mspi3>,
             <&CLK_ns_top_i_0>,
             <&CLK_ns_top_i_1>,
             <&CLK_ns_top_i_2>,
             <&CLK_ns_top_i_3>,
             <&CLK_nuc>,
             <&CLK_otp>,
             <&CLK_otp_p>,
             <&CLK_pad_test>,
             <&CLK_pir_pm>,
             <&CLK_pm_fuart0>,
             <&CLK_pm_miic0>,
             <&CLK_pm_miic1>,
             <&CLK_pm_mspi0>,
             <&CLK_pm_mspi1>,
             <&CLK_pm_pspi0>,
             <&CLK_pm_pwm>,
             <&CLK_pm_pwr_ctl>,
             <&CLK_pm_riu_w_clk_in>,
             <&CLK_pm_sleep>,
             <&CLK_pm_uart0>,
             <&CLK_pwm>,
             <&CLK_pwr_ctl>,
             <&CLK_radar_adc>,
             <&CLK_real_live>,
             <&CLK_riscvpll_clk>,
             <&CLK_riu_w_clk_hemcu_gp>,
             <&CLK_riu_w_clk_in>,
             <&CLK_riu_w_clk_mcu_if_gp>,
             <&CLK_riu_w_clk_mipi_if_gp>,
             <&CLK_riu_w_clk_sc_gp>,
             <&CLK_riu_w_clk_top>,
             <&CLK_riu_w_clk_vhe_gp>,
             <&CLK_riubrdg>,
             <&CLK_rmii_buf>,
             <&CLK_rtc>,
             <&CLK_rtcpll_clk>,
             <&CLK_rtcpll_clk_div128>,
             <&CLK_rtcpll_clk_div16>,
             <&CLK_rtcpll_clk_div192>,
             <&CLK_rtcpll_clk_div2>,
             <&CLK_rtcpll_clk_div256>,
             <&CLK_rtcpll_clk_div32>,
             <&CLK_rtcpll_clk_div384>,
             <&CLK_rtcpll_clk_div4>,
             <&CLK_rtcpll_clk_div48>,
             <&CLK_rtcpll_clk_div6>,
             <&CLK_rtcpll_clk_div64>,
             <&CLK_rtcpll_clk_div8>,
             <&CLK_rtcpll_clk_div96>,
             <&CLK_sar>,
             <&CLK_sc_disp_216>,
             <&CLK_sd>,
             <&CLK_sd_1x_p>,
             <&CLK_sd_2x_p>,
             <&CLK_sd_syn>,
             <&CLK_sdio>,
             <&CLK_sof_usb30_drd>,
             <&CLK_spi>,
             <&CLK_spi_pm>,
             <&CLK_spi_synth_pll>,
             <&CLK_sr00_mclk>,
             <&CLK_sr01_mclk>,
             <&CLK_sr02_mclk>,
             <&CLK_sr03_mclk>,
             <&CLK_sr10_mclk>,
             <&CLK_sr11_mclk>,
             <&CLK_sr12_mclk>,
             <&CLK_sr13_mclk>,
             <&CLK_sr_mclk>,
             <&CLK_sr_mclk_pm>,
             <&CLK_ssi_dphy>,
             <&CLK_ssm0>,
             <&CLK_ssm1>,
             <&CLK_ssusb_axi>,
             <&CLK_ssusb_phy_108>,
             <&CLK_ssusb_phy_432>,
             <&CLK_tck_buf>,
             <&CLK_upll_20m>,
             <&CLK_upll_320m>,
             <&CLK_upll_320m_div10>,
             <&CLK_upll_320m_div16>,
             <&CLK_upll_320m_div2>,
             <&CLK_upll_320m_div20>,
             <&CLK_upll_320m_div8>,
             <&CLK_upll_384m>,
             <&CLK_upll_384m_div2>,
             <&CLK_upll_384m_div4>,
             <&CLK_upll_384m_div8>,
             <&CLK_upll_480m>,
             <&CLK_upll_480m_div2>,
             <&CLK_upll_radar_20m>,
             <&CLK_usb_32k>,
             <&CLK_ven_axi>,
             <&CLK_ven_pll>,
             <&CLK_ven_sc_if>,
             <&CLK_ven_scdn>,
             <&CLK_venpll_clk>,
             <&CLK_vhe>,
             <&CLK_wdt>,
             <&CLK_xtal_usb30_drd>,
             <&CLK_xtali>,
             <&CLK_xtali_12m>,
             <&CLK_xtali_12m_div128>,
             <&CLK_xtali_12m_div16>,
             <&CLK_xtali_12m_div2>,
             <&CLK_xtali_12m_div375>,
             <&CLK_xtali_12m_div4>,
             <&CLK_xtali_12m_div40>,
             <&CLK_xtali_12m_div64>,
             <&CLK_xtali_12m_div8>,
             <&CLK_xtali_12m_v_live>,
             <&CLK_xtali_24>,
             <&CLK_xtali_24m>,
             <&CLK_wdma>,
             <&CLK_gmacpll_top>,
             <&CLK_rng>,
             <&CLK_boot_p>;
    clock-count = <274>;
};
#endif
